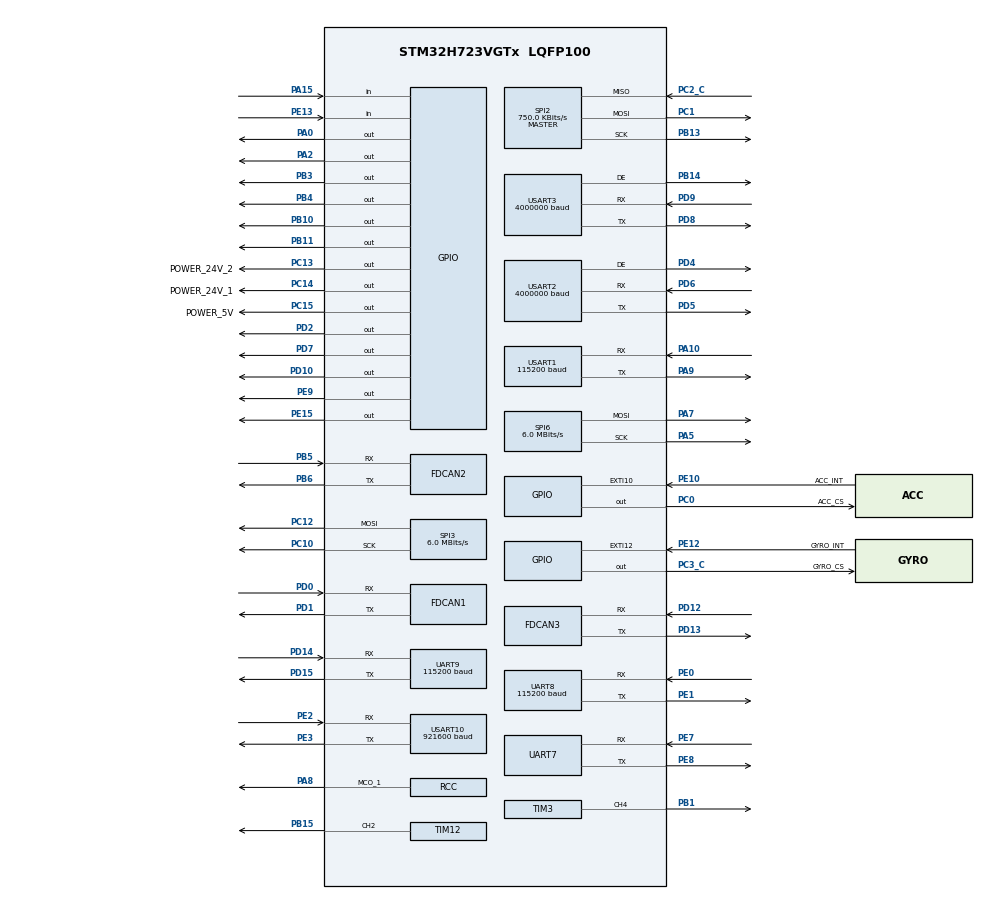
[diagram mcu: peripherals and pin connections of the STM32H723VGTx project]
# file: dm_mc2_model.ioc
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CORTEX_M7.default_mode_Activation=1
Dma.Request0=USART2_RX
Dma.Request1=USART2_TX
Dma.Request10=USART1_RX
Dma.Request11=USART1_TX
Dma.Request12=UART8_RX
Dma.Request13=UART8_TX
Dma.Request14=UART9_TX
Dma.Request15=USART10_TX
Dma.Request2=USART3_RX
Dma.Request3=USART3_TX
Dma.Request4=SPI2_RX
Dma.Request5=SPI2_TX
Dma.Request6=USART10_RX
Dma.Request7=UART7_RX
Dma.Request8=UART7_TX
Dma.Request9=UART9_RX
Dma.SPI2_RX.4.Direction=DMA_PERIPH_TO_MEMORY
Dma.SPI2_RX.4.EventEnable=DISABLE
Dma.SPI2_RX.4.FIFOMode=DMA_FIFOMODE_DISABLE
Dma.SPI2_RX.4.Instance=DMA1_Stream4
Dma.SPI2_RX.4.MemDataAlignment=DMA_MDATAALIGN_BYTE
Dma.SPI2_RX.4.MemInc=DMA_MINC_ENABLE
Dma.SPI2_RX.4.Mode=DMA_NORMAL
Dma.SPI2_RX.4.PeriphDataAlignment=DMA_PDATAALIGN_BYTE
Dma.SPI2_RX.4.PeriphInc=DMA_PINC_DISABLE
Dma.SPI2_RX.4.Polarity=HAL_DMAMUX_REQ_GEN_RISING
Dma.SPI2_RX.4.Priority=DMA_PRIORITY_VERY_HIGH
Dma.SPI2_RX.4.RequestNumber=1
Dma.SPI2_RX.4.SignalID=NONE
Dma.SPI2_RX.4.SyncEnable=DISABLE
Dma.SPI2_RX.4.SyncPolarity=HAL_DMAMUX_SYNC_NO_EVENT
Dma.SPI2_RX.4.SyncRequestNumber=1
Dma.SPI2_RX.4.SyncSignalID=NONE
Dma.SPI2_TX.5.Direction=DMA_MEMORY_TO_PERIPH
Dma.SPI2_TX.5.EventEnable=DISABLE
Dma.SPI2_TX.5.FIFOMode=DMA_FIFOMODE_DISABLE
Dma.SPI2_TX.5.Instance=DMA1_Stream5
Dma.SPI2_TX.5.MemDataAlignment=DMA_MDATAALIGN_BYTE
Dma.SPI2_TX.5.MemInc=DMA_MINC_ENABLE
Dma.SPI2_TX.5.Mode=DMA_NORMAL
Dma.SPI2_TX.5.PeriphDataAlignment=DMA_PDATAALIGN_BYTE
Dma.SPI2_TX.5.PeriphInc=DMA_PINC_DISABLE
Dma.SPI2_TX.5.Polarity=HAL_DMAMUX_REQ_GEN_RISING
Dma.SPI2_TX.5.Priority=DMA_PRIORITY_HIGH
Dma.SPI2_TX.5.RequestNumber=1
Dma.SPI2_TX.5.SignalID=NONE
Dma.SPI2_TX.5.SyncEnable=DISABLE
Dma.SPI2_TX.5.SyncPolarity=HAL_DMAMUX_SYNC_NO_EVENT
Dma.SPI2_TX.5.SyncRequestNumber=1
Dma.SPI2_TX.5.SyncSignalID=NONE
Dma.UART7_RX.7.Direction=DMA_PERIPH_TO_MEMORY
Dma.UART7_RX.7.EventEnable=DISABLE
Dma.UART7_RX.7.FIFOMode=DMA_FIFOMODE_DISABLE
Dma.UART7_RX.7.Instance=DMA1_Stream7
Dma.UART7_RX.7.MemDataAlignment=DMA_MDATAALIGN_BYTE
Dma.UART7_RX.7.MemInc=DMA_MINC_ENABLE
Dma.UART7_RX.7.Mode=DMA_NORMAL
Dma.UART7_RX.7.PeriphDataAlignment=DMA_PDATAALIGN_BYTE
Dma.UART7_RX.7.PeriphInc=DMA_PINC_DISABLE
Dma.UART7_RX.7.Polarity=HAL_DMAMUX_REQ_GEN_RISING
Dma.UART7_RX.7.Priority=DMA_PRIORITY_LOW
Dma.UART7_RX.7.RequestNumber=1
Dma.UART7_RX.7.SignalID=NONE
Dma.UART7_RX.7.SyncEnable=DISABLE
Dma.UART7_RX.7.SyncPolarity=HAL_DMAMUX_SYNC_NO_EVENT
Dma.UART7_RX.7.SyncRequestNumber=1
Dma.UART7_RX.7.SyncSignalID=NONE
Dma.UART7_TX.8.Direction=DMA_MEMORY_TO_PERIPH
Dma.UART7_TX.8.EventEnable=DISABLE
Dma.UART7_TX.8.FIFOMode=DMA_FIFOMODE_DISABLE
Dma.UART7_TX.8.Instance=DMA2_Stream0
Dma.UART7_TX.8.MemDataAlignment=DMA_MDATAALIGN_BYTE
Dma.UART7_TX.8.MemInc=DMA_MINC_ENABLE
Dma.UART7_TX.8.Mode=DMA_NORMAL
Dma.UART7_TX.8.PeriphDataAlignment=DMA_PDATAALIGN_BYTE
Dma.UART7_TX.8.PeriphInc=DMA_PINC_DISABLE
Dma.UART7_TX.8.Polarity=HAL_DMAMUX_REQ_GEN_RISING
Dma.UART7_TX.8.Priority=DMA_PRIORITY_LOW
Dma.UART7_TX.8.RequestNumber=1
Dma.UART7_TX.8.SignalID=NONE
Dma.UART7_TX.8.SyncEnable=DISABLE
Dma.UART7_TX.8.SyncPolarity=HAL_DMAMUX_SYNC_NO_EVENT
Dma.UART7_TX.8.SyncRequestNumber=1
Dma.UART7_TX.8.SyncSignalID=NONE
Dma.UART8_RX.12.Direction=DMA_PERIPH_TO_MEMORY
Dma.UART8_RX.12.EventEnable=DISABLE
Dma.UART8_RX.12.FIFOMode=DMA_FIFOMODE_DISABLE
Dma.UART8_RX.12.Instance=DMA2_Stream4
Dma.UART8_RX.12.MemDataAlignment=DMA_MDATAALIGN_BYTE
Dma.UART8_RX.12.MemInc=DMA_MINC_ENABLE
Dma.UART8_RX.12.Mode=DMA_NORMAL
Dma.UART8_RX.12.PeriphDataAlignment=DMA_PDATAALIGN_BYTE
Dma.UART8_RX.12.PeriphInc=DMA_PINC_DISABLE
Dma.UART8_RX.12.Polarity=HAL_DMAMUX_REQ_GEN_RISING
Dma.UART8_RX.12.Priority=DMA_PRIORITY_LOW
Dma.UART8_RX.12.RequestNumber=1
Dma.UART8_RX.12.SignalID=NONE
Dma.UART8_RX.12.SyncEnable=DISABLE
Dma.UART8_RX.12.SyncPolarity=HAL_DMAMUX_SYNC_NO_EVENT
Dma.UART8_RX.12.SyncRequestNumber=1
Dma.UART8_RX.12.SyncSignalID=NONE
Dma.UART8_TX.13.Direction=DMA_MEMORY_TO_PERIPH
Dma.UART8_TX.13.EventEnable=DISABLE
Dma.UART8_TX.13.FIFOMode=DMA_FIFOMODE_DISABLE
Dma.UART8_TX.13.Instance=DMA2_Stream5
Dma.UART8_TX.13.MemDataAlignment=DMA_MDATAALIGN_BYTE
Dma.UART8_TX.13.MemInc=DMA_MINC_ENABLE
Dma.UART8_TX.13.Mode=DMA_NORMAL
Dma.UART8_TX.13.PeriphDataAlignment=DMA_PDATAALIGN_BYTE
Dma.UART8_TX.13.PeriphInc=DMA_PINC_DISABLE
Dma.UART8_TX.13.Polarity=HAL_DMAMUX_REQ_GEN_RISING
Dma.UART8_TX.13.Priority=DMA_PRIORITY_LOW
Dma.UART8_TX.13.RequestNumber=1
Dma.UART8_TX.13.SignalID=NONE
Dma.UART8_TX.13.SyncEnable=DISABLE
Dma.UART8_TX.13.SyncPolarity=HAL_DMAMUX_SYNC_NO_EVENT
Dma.UART8_TX.13.SyncRequestNumber=1
Dma.UART8_TX.13.SyncSignalID=NONE
Dma.UART9_RX.9.Direction=DMA_PERIPH_TO_MEMORY
Dma.UART9_RX.9.EventEnable=DISABLE
Dma.UART9_RX.9.FIFOMode=DMA_FIFOMODE_DISABLE
Dma.UART9_RX.9.Instance=DMA2_Stream1
Dma.UART9_RX.9.MemDataAlignment=DMA_MDATAALIGN_BYTE
Dma.UART9_RX.9.MemInc=DMA_MINC_ENABLE
Dma.UART9_RX.9.Mode=DMA_NORMAL
Dma.UART9_RX.9.PeriphDataAlignment=DMA_PDATAALIGN_BYTE
Dma.UART9_RX.9.PeriphInc=DMA_PINC_DISABLE
Dma.UART9_RX.9.Polarity=HAL_DMAMUX_REQ_GEN_RISING
Dma.UART9_RX.9.Priority=DMA_PRIORITY_LOW
Dma.UART9_RX.9.RequestNumber=1
Dma.UART9_RX.9.SignalID=NONE
Dma.UART9_RX.9.SyncEnable=DISABLE
Dma.UART9_RX.9.SyncPolarity=HAL_DMAMUX_SYNC_NO_EVENT
Dma.UART9_RX.9.SyncRequestNumber=1
Dma.UART9_RX.9.SyncSignalID=NONE
Dma.UART9_TX.14.Direction=DMA_MEMORY_TO_PERIPH
Dma.UART9_TX.14.EventEnable=DISABLE
Dma.UART9_TX.14.FIFOMode=DMA_FIFOMODE_DISABLE
Dma.UART9_TX.14.Instance=DMA2_Stream6
Dma.UART9_TX.14.MemDataAlignment=DMA_MDATAALIGN_BYTE
Dma.UART9_TX.14.MemInc=DMA_MINC_ENABLE
Dma.UART9_TX.14.Mode=DMA_NORMAL
Dma.UART9_TX.14.PeriphDataAlignment=DMA_PDATAALIGN_BYTE
Dma.UART9_TX.14.PeriphInc=DMA_PINC_DISABLE
Dma.UART9_TX.14.Polarity=HAL_DMAMUX_REQ_GEN_RISING
Dma.UART9_TX.14.Priority=DMA_PRIORITY_LOW
Dma.UART9_TX.14.RequestNumber=1
Dma.UART9_TX.14.SignalID=NONE
Dma.UART9_TX.14.SyncEnable=DISABLE
Dma.UART9_TX.14.SyncPolarity=HAL_DMAMUX_SYNC_NO_EVENT
Dma.UART9_TX.14.SyncRequestNumber=1
Dma.UART9_TX.14.SyncSignalID=NONE
Dma.USART10_RX.6.Direction=DMA_PERIPH_TO_MEMORY
Dma.USART10_RX.6.EventEnable=DISABLE
Dma.USART10_RX.6.FIFOMode=DMA_FIFOMODE_DISABLE
Dma.USART10_RX.6.Instance=DMA1_Stream6
Dma.USART10_RX.6.MemDataAlignment=DMA_MDATAALIGN_BYTE
Dma.USART10_RX.6.MemInc=DMA_MINC_ENABLE
Dma.USART10_RX.6.Mode=DMA_NORMAL
Dma.USART10_RX.6.PeriphDataAlignment=DMA_PDATAALIGN_BYTE
Dma.USART10_RX.6.PeriphInc=DMA_PINC_DISABLE
Dma.USART10_RX.6.Polarity=HAL_DMAMUX_REQ_GEN_RISING
Dma.USART10_RX.6.Priority=DMA_PRIORITY_LOW
Dma.USART10_RX.6.RequestNumber=1
Dma.USART10_RX.6.SignalID=NONE
Dma.USART10_RX.6.SyncEnable=DISABLE
Dma.USART10_RX.6.SyncPolarity=HAL_DMAMUX_SYNC_NO_EVENT
Dma.USART10_RX.6.SyncRequestNumber=1
Dma.USART10_RX.6.SyncSignalID=NONE
Dma.USART10_TX.15.Direction=DMA_MEMORY_TO_PERIPH
Dma.USART10_TX.15.EventEnable=DISABLE
Dma.USART10_TX.15.FIFOMode=DMA_FIFOMODE_DISABLE
Dma.USART10_TX.15.Instance=DMA2_Stream7
Dma.USART10_TX.15.MemDataAlignment=DMA_MDATAALIGN_BYTE
Dma.USART10_TX.15.MemInc=DMA_MINC_ENABLE
Dma.USART10_TX.15.Mode=DMA_NORMAL
Dma.USART10_TX.15.PeriphDataAlignment=DMA_PDATAALIGN_BYTE
Dma.USART10_TX.15.PeriphInc=DMA_PINC_DISABLE
Dma.USART10_TX.15.Polarity=HAL_DMAMUX_REQ_GEN_RISING
Dma.USART10_TX.15.Priority=DMA_PRIORITY_LOW
Dma.USART10_TX.15.RequestNumber=1
Dma.USART10_TX.15.SignalID=NONE
Dma.USART10_TX.15.SyncEnable=DISABLE
Dma.USART10_TX.15.SyncPolarity=HAL_DMAMUX_SYNC_NO_EVENT
Dma.USART10_TX.15.SyncRequestNumber=1
Dma.USART10_TX.15.SyncSignalID=NONE
Dma.USART1_RX.10.Direction=DMA_PERIPH_TO_MEMORY
Dma.USART1_RX.10.EventEnable=DISABLE
Dma.USART1_RX.10.FIFOMode=DMA_FIFOMODE_DISABLE
Dma.USART1_RX.10.Instance=DMA2_Stream2
Dma.USART1_RX.10.MemDataAlignment=DMA_MDATAALIGN_BYTE
Dma.USART1_RX.10.MemInc=DMA_MINC_ENABLE
Dma.USART1_RX.10.Mode=DMA_NORMAL
Dma.USART1_RX.10.PeriphDataAlignment=DMA_PDATAALIGN_BYTE
Dma.USART1_RX.10.PeriphInc=DMA_PINC_DISABLE
Dma.USART1_RX.10.Polarity=HAL_DMAMUX_REQ_GEN_RISING
Dma.USART1_RX.10.Priority=DMA_PRIORITY_LOW
Dma.USART1_RX.10.RequestNumber=1
Dma.USART1_RX.10.SignalID=NONE
Dma.USART1_RX.10.SyncEnable=DISABLE
Dma.USART1_RX.10.SyncPolarity=HAL_DMAMUX_SYNC_NO_EVENT
Dma.USART1_RX.10.SyncRequestNumber=1
Dma.USART1_RX.10.SyncSignalID=NONE
Dma.USART1_TX.11.Direction=DMA_MEMORY_TO_PERIPH
Dma.USART1_TX.11.EventEnable=DISABLE
Dma.USART1_TX.11.FIFOMode=DMA_FIFOMODE_DISABLE
Dma.USART1_TX.11.Instance=DMA2_Stream3
Dma.USART1_TX.11.MemDataAlignment=DMA_MDATAALIGN_BYTE
Dma.USART1_TX.11.MemInc=DMA_MINC_ENABLE
Dma.USART1_TX.11.Mode=DMA_NORMAL
Dma.USART1_TX.11.PeriphDataAlignment=DMA_PDATAALIGN_BYTE
Dma.USART1_TX.11.PeriphInc=DMA_PINC_DISABLE
Dma.USART1_TX.11.Polarity=HAL_DMAMUX_REQ_GEN_RISING
Dma.USART1_TX.11.Priority=DMA_PRIORITY_LOW
Dma.USART1_TX.11.RequestNumber=1
Dma.USART1_TX.11.SignalID=NONE
Dma.USART1_TX.11.SyncEnable=DISABLE
Dma.USART1_TX.11.SyncPolarity=HAL_DMAMUX_SYNC_NO_EVENT
Dma.USART1_TX.11.SyncRequestNumber=1
Dma.USART1_TX.11.SyncSignalID=NONE
Dma.USART2_RX.0.Direction=DMA_PERIPH_TO_MEMORY
Dma.USART2_RX.0.EventEnable=DISABLE
Dma.USART2_RX.0.FIFOMode=DMA_FIFOMODE_DISABLE
Dma.USART2_RX.0.Instance=DMA1_Stream0
Dma.USART2_RX.0.MemDataAlignment=DMA_MDATAALIGN_BYTE
Dma.USART2_RX.0.MemInc=DMA_MINC_ENABLE
Dma.USART2_RX.0.Mode=DMA_NORMAL
Dma.USART2_RX.0.PeriphDataAlignment=DMA_PDATAALIGN_BYTE
Dma.USART2_RX.0.PeriphInc=DMA_PINC_DISABLE
Dma.USART2_RX.0.Polarity=HAL_DMAMUX_REQ_GEN_RISING
Dma.USART2_RX.0.Priority=DMA_PRIORITY_LOW
Dma.USART2_RX.0.RequestNumber=1
Dma.USART2_RX.0.SignalID=NONE
Dma.USART2_RX.0.SyncEnable=DISABLE
Dma.USART2_RX.0.SyncPolarity=HAL_DMAMUX_SYNC_NO_EVENT
Dma.USART2_RX.0.SyncRequestNumber=1
Dma.USART2_RX.0.SyncSignalID=NONE
Dma.USART2_TX.1.Direction=DMA_MEMORY_TO_PERIPH
Dma.USART2_TX.1.EventEnable=DISABLE
Dma.USART2_TX.1.FIFOMode=DMA_FIFOMODE_DISABLE
Dma.USART2_TX.1.Instance=DMA1_Stream1
Dma.USART2_TX.1.MemDataAlignment=DMA_MDATAALIGN_BYTE
Dma.USART2_TX.1.MemInc=DMA_MINC_ENABLE
Dma.USART2_TX.1.Mode=DMA_NORMAL
Dma.USART2_TX.1.PeriphDataAlignment=DMA_PDATAALIGN_BYTE
Dma.USART2_TX.1.PeriphInc=DMA_PINC_DISABLE
Dma.USART2_TX.1.Polarity=HAL_DMAMUX_REQ_GEN_RISING
Dma.USART2_TX.1.Priority=DMA_PRIORITY_LOW
Dma.USART2_TX.1.RequestNumber=1
Dma.USART2_TX.1.SignalID=NONE
Dma.USART2_TX.1.SyncEnable=DISABLE
Dma.USART2_TX.1.SyncPolarity=HAL_DMAMUX_SYNC_NO_EVENT
Dma.USART2_TX.1.SyncRequestNumber=1
Dma.USART2_TX.1.SyncSignalID=NONE
Dma.USART3_RX.2.Direction=DMA_PERIPH_TO_MEMORY
Dma.USART3_RX.2.EventEnable=DISABLE
Dma.USART3_RX.2.FIFOMode=DMA_FIFOMODE_DISABLE
Dma.USART3_RX.2.Instance=DMA1_Stream2
Dma.USART3_RX.2.MemDataAlignment=DMA_MDATAALIGN_BYTE
Dma.USART3_RX.2.MemInc=DMA_MINC_ENABLE
Dma.USART3_RX.2.Mode=DMA_NORMAL
Dma.USART3_RX.2.PeriphDataAlignment=DMA_PDATAALIGN_BYTE
Dma.USART3_RX.2.PeriphInc=DMA_PINC_DISABLE
Dma.USART3_RX.2.Polarity=HAL_DMAMUX_REQ_GEN_RISING
Dma.USART3_RX.2.Priority=DMA_PRIORITY_LOW
Dma.USART3_RX.2.RequestNumber=1
Dma.USART3_RX.2.SignalID=NONE
Dma.USART3_RX.2.SyncEnable=DISABLE
Dma.USART3_RX.2.SyncPolarity=HAL_DMAMUX_SYNC_NO_EVENT
Dma.USART3_RX.2.SyncRequestNumber=1
Dma.USART3_RX.2.SyncSignalID=NONE
Dma.USART3_TX.3.Direction=DMA_MEMORY_TO_PERIPH
Dma.USART3_TX.3.EventEnable=DISABLE
Dma.USART3_TX.3.FIFOMode=DMA_FIFOMODE_DISABLE
Dma.USART3_TX.3.Instance=DMA1_Stream3
Dma.USART3_TX.3.MemDataAlignment=DMA_MDATAALIGN_BYTE
Dma.USART3_TX.3.MemInc=DMA_MINC_ENABLE
Dma.USART3_TX.3.Mode=DMA_NORMAL
Dma.USART3_TX.3.PeriphDataAlignment=DMA_PDATAALIGN_BYTE
Dma.USART3_TX.3.PeriphInc=DMA_PINC_DISABLE
Dma.USART3_TX.3.Polarity=HAL_DMAMUX_REQ_GEN_RISING
Dma.USART3_TX.3.Priority=DMA_PRIORITY_LOW
Dma.USART3_TX.3.RequestNumber=1
Dma.USART3_TX.3.SignalID=NONE
Dma.USART3_TX.3.SyncEnable=DISABLE
Dma.USART3_TX.3.SyncPolarity=HAL_DMAMUX_SYNC_NO_EVENT
Dma.USART3_TX.3.SyncRequestNumber=1
Dma.USART3_TX.3.SyncSignalID=NONE
FDCAN1.CalculateBaudRateNominal=1000000
FDCAN1.CalculateTimeBitNominal=1000
FDCAN1.CalculateTimeQuantumNominal=200.0
FDCAN1.NominalPrescaler=24
FDCAN1.NominalTimeSeg1=2
FDCAN1.NominalTimeSeg2=2
FDCAN1.RxFifo0ElmtsNbr=32
FDCAN1.StdFiltersNbr=1
FDCAN1.TxFifoQueueElmtsNbr=32
FDCAN2.CalculateBaudRateNominal=1000000
FDCAN2.CalculateTimeBitNominal=1000
FDCAN2.CalculateTimeQuantumNominal=100.0
FDCAN2.MessageRAMOffset=0x406
FDCAN2.NominalPrescaler=12
FDCAN2.NominalSyncJumpWidth=2
FDCAN2.NominalTimeSeg1=7
FDCAN2.NominalTimeSeg2=2
FDCAN2.RxFifo0ElmtsNbr=32
FDCAN2.StdFiltersNbr=1
FDCAN2.TxFifoQueueElmtsNbr=32
FDCAN3.CalculateBaudRateNominal=1000000
FDCAN3.CalculateTimeBitNominal=1000
FDCAN3.CalculateTimeQuantumNominal=200.0
FDCAN3.MessageRAMOffset=0x812
FDCAN3.NominalPrescaler=24
FDCAN3.NominalTimeSeg1=2
FDCAN3.NominalTimeSeg2=2
FDCAN3.RxFifo0ElmtsNbr=32
FDCAN3.StdFiltersNbr=1
FDCAN3.TxFifoQueueElmtsNbr=32
FREERTOS.Tasks01=defaultTask,24,128,StartDefaultTask,Default,NULL,Dynamic,NULL,NULL;Unitree,8,128,Unitree_Function,Default,NULL,Dynamic,NULL,NULL;DM,8,128,DM_Function,Default,NULL,Dynamic,NULL,NULL;DJI,8,128,DJI_Function,Default,NULL,Dynamic,NULL,NULL;Remote,8,128,Remote_Function,Default,NULL,Dynamic,NULL,NULL;DH_C,8,128,DH_C_Function,Default,NULL,Dynamic,NULL,NULL;Remote_mode,8,128,Remote_mode_function,Default,NULL,Dynamic,NULL,NULL;inverseKinemati,8,128,inverseKinematics_Function,Default,NULL,Dynamic,NULL,NULL;Angle_ring,8,128,Angle_ring_Function,Default,NULL,Dynamic,NULL,NULL;L1_Mode,8,128,L1_Mode_Function,Default,NULL,Dynamic,NULL,NULL;Lift_Mode,8,128,Lift_Mode_Function,Default,NULL,Dynamic,NULL,NULL;One_Area,8,128,One_Area_Function,Default,NULL,Dynamic,NULL,NULL;Two_Area,8,128,Two_Area_Function,Default,NULL,Dynamic,NULL,NULL;Three_Area,8,128,Three_Area_Function,Default,NULL,Dynamic,NULL,NULL;Mid360,8,128,Mid360_Function,Default,NULL,Dynamic,NULL,NULL;Track_Mode,8,128,Track_Mode_Function,Default,NULL,Dynamic,NULL,NULL
Mcu.Family=STM32H7
Mcu.Name=STM32H723VGTx
Mcu.Package=LQFP100
NVIC.DMA1_Stream0_IRQn=true\:5\:0\:false\:false\:true\:true\:false\:true\:true
NVIC.DMA1_Stream1_IRQn=true\:5\:0\:false\:false\:true\:true\:false\:true\:true
NVIC.DMA1_Stream2_IRQn=true\:5\:0\:false\:false\:true\:true\:false\:true\:true
NVIC.DMA1_Stream3_IRQn=true\:5\:0\:false\:false\:true\:true\:false\:true\:true
NVIC.DMA1_Stream4_IRQn=true\:5\:0\:false\:false\:true\:true\:false\:true\:true
NVIC.DMA1_Stream5_IRQn=true\:5\:0\:false\:false\:true\:true\:false\:true\:true
NVIC.DMA1_Stream6_IRQn=true\:5\:0\:false\:false\:true\:true\:false\:true\:true
NVIC.DMA1_Stream7_IRQn=true\:5\:0\:false\:false\:true\:true\:false\:true\:true
NVIC.DMA2_Stream0_IRQn=true\:5\:0\:false\:false\:true\:true\:false\:true\:true
NVIC.DMA2_Stream1_IRQn=true\:5\:0\:false\:false\:true\:true\:false\:true\:true
NVIC.DMA2_Stream2_IRQn=true\:5\:0\:false\:false\:true\:true\:false\:true\:true
NVIC.DMA2_Stream3_IRQn=true\:5\:0\:false\:false\:true\:true\:false\:true\:true
NVIC.DMA2_Stream4_IRQn=true\:5\:0\:false\:false\:true\:true\:false\:true\:true
NVIC.DMA2_Stream5_IRQn=true\:5\:0\:false\:false\:true\:true\:false\:true\:true
NVIC.DMA2_Stream6_IRQn=true\:5\:0\:false\:false\:true\:true\:false\:true\:true
NVIC.DMA2_Stream7_IRQn=true\:5\:0\:false\:false\:true\:true\:false\:true\:true
NVIC.FDCAN1_IT0_IRQn=true\:5\:0\:false\:false\:true\:true\:true\:true\:true
NVIC.FDCAN1_IT1_IRQn=true\:5\:0\:false\:false\:true\:true\:true\:true\:true
NVIC.FDCAN2_IT0_IRQn=true\:5\:0\:false\:false\:true\:true\:true\:true\:true
NVIC.FDCAN2_IT1_IRQn=true\:5\:0\:false\:false\:true\:true\:true\:true\:true
NVIC.FDCAN3_IT0_IRQn=true\:5\:0\:false\:false\:true\:true\:true\:true\:true
NVIC.FDCAN3_IT1_IRQn=true\:5\:0\:false\:false\:true\:true\:true\:true\:true
NVIC.PriorityGroup=NVIC_PRIORITYGROUP_4
NVIC.SPI2_IRQn=true\:5\:0\:false\:false\:true\:true\:false\:true\:true
NVIC.TIM23_IRQn=true\:15\:0\:false\:false\:true\:false\:false\:true\:true
NVIC.TIM6_DAC_IRQn=true\:5\:0\:false\:false\:true\:true\:true\:true\:true
NVIC.TimeBase=TIM23_IRQn
NVIC.TimeBaseIP=TIM23
NVIC.UART7_IRQn=true\:5\:0\:false\:false\:true\:true\:true\:true\:true
NVIC.UART8_IRQn=true\:5\:0\:false\:false\:true\:true\:true\:true\:true
NVIC.UART9_IRQn=true\:5\:0\:false\:false\:true\:true\:true\:true\:true
NVIC.USART10_IRQn=true\:5\:0\:false\:false\:true\:true\:true\:true\:true
NVIC.USART1_IRQn=true\:5\:0\:false\:false\:true\:true\:true\:true\:true
NVIC.USART2_IRQn=true\:5\:0\:false\:false\:true\:true\:true\:true\:true
NVIC.USART3_IRQn=true\:5\:0\:false\:false\:true\:true\:true\:true\:true
PA0.Signal=GPIO_Output
PA1.Signal=OCTOSPIM_P1_IO3
PA10.Mode=Asynchronous
PA10.Signal=USART1_RX
PA13(JTMS/SWDIO).Mode=Serial_Wire
PA13(JTMS/SWDIO).Signal=DEBUG_JTMS-SWDIO
PA14(JTCK/SWCLK).Mode=Serial_Wire
PA14(JTCK/SWCLK).Signal=DEBUG_JTCK-SWCLK
PA15(JTDI).Signal=GPIO_Input
PA2.Signal=GPIO_Output
PA3.Signal=OCTOSPIM_P1_IO2
PA5.Mode=TX_Only_Simplex_Unidirect_Master
PA5.Signal=SPI6_SCK
PA7.GPIO_Speed=GPIO_SPEED_FREQ_VERY_HIGH
PA7.Mode=TX_Only_Simplex_Unidirect_Master
PA7.Signal=SPI6_MOSI
PA8.Mode=Clock-out-1
PA8.Signal=RCC_MCO_1
PA9.Mode=Asynchronous
PA9.Signal=USART1_TX
PB1.Signal=S_TIM3_CH4
PB10.Signal=GPIO_Output
PB11.Signal=GPIO_Output
PB13.Mode=Full_Duplex_Master
PB13.Signal=SPI2_SCK
PB14.Mode=Hardware Flow Control (RS485)
PB14.Signal=USART3_DE
PB15.Signal=S_TIM12_CH2
PB3(JTDO/TRACESWO).Signal=GPIO_Output
PB4(NJTRST).Signal=GPIO_Output
PB5.Mode=FDCAN_Activate
PB5.Signal=FDCAN2_RX
PB6.Mode=FDCAN_Activate
PB6.Signal=FDCAN2_TX
PC0.GPIO_Label=ACC_CS
PC0.GPIO_Speed=GPIO_SPEED_FREQ_VERY_HIGH
PC0.PinState=GPIO_PIN_SET
PC0.Signal=GPIO_Output
PC1.Mode=Full_Duplex_Master
PC1.Signal=SPI2_MOSI
PC10.Mode=TX_Only_Simplex_Unidirect_Master
PC10.Signal=SPI3_SCK
PC11.Signal=SPI3_MISO
PC12.Mode=TX_Only_Simplex_Unidirect_Master
PC12.Signal=SPI3_MOSI
PC13.GPIO_Label=POWER_24V_2
PC13.PinState=GPIO_PIN_SET
PC13.Signal=GPIO_Output
PC14-OSC32_IN.GPIO_Label=POWER_24V_1
PC14-OSC32_IN.PinState=GPIO_PIN_SET
PC14-OSC32_IN.Signal=GPIO_Output
PC15-OSC32_OUT.GPIO_Label=POWER_5V
PC15-OSC32_OUT.PinState=GPIO_PIN_SET
PC15-OSC32_OUT.Signal=GPIO_Output
PC2_C.Mode=Full_Duplex_Master
PC2_C.Signal=SPI2_MISO
PC3_C.GPIO_Label=GYRO_CS
PC3_C.GPIO_Speed=GPIO_SPEED_FREQ_VERY_HIGH
PC3_C.PinState=GPIO_PIN_SET
PC3_C.Signal=GPIO_Output
PD0.Mode=FDCAN_Activate
PD0.Signal=FDCAN1_RX
PD1.Mode=FDCAN_Activate
PD1.Signal=FDCAN1_TX
PD10.Signal=GPIO_Output
PD12.Mode=FDCAN_Activate
PD12.Signal=FDCAN3_RX
PD13.Mode=FDCAN_Activate
PD13.Signal=FDCAN3_TX
PD14.Mode=Asynchronous
PD14.Signal=UART9_RX
PD15.Mode=Asynchronous
PD15.Signal=UART9_TX
PD2.Signal=GPIO_Output
PD4.Mode=Hardware Flow Control (RS485)
PD4.Signal=USART2_DE
PD5.Mode=Asynchronous
PD5.Signal=USART2_TX
PD6.Mode=Asynchronous
PD6.Signal=USART2_RX
PD7.Signal=GPIO_Output
PD8.Mode=Asynchronous
PD8.Signal=USART3_TX
PD9.Mode=Asynchronous
PD9.Signal=USART3_RX
PE0.Mode=Asynchronous
PE0.Signal=UART8_RX
PE1.Mode=Asynchronous
PE1.Signal=UART8_TX
PE10.GPIO_Label=ACC_INT
PE10.Signal=GPXTI10
PE12.GPIO_Label=GYRO_INT
PE12.Signal=GPXTI12
PE13.GPIO_PuPd=GPIO_NOPULL
PE13.Signal=GPIO_Input
PE15.Signal=GPIO_Output
PE2.Mode=Asynchronous
PE2.Signal=USART10_RX
PE3.Mode=Asynchronous
PE3.Signal=USART10_TX
PE7.Mode=Asynchronous
PE7.Signal=UART7_RX
PE8.Mode=Asynchronous
PE8.Signal=UART7_TX
PE9.Signal=GPIO_Output
PH0-OSC_IN.Mode=HSE-External-Oscillator
PH0-OSC_IN.Signal=RCC_OSC_IN
PH1-OSC_OUT.Mode=HSE-External-Oscillator
PH1-OSC_OUT.Signal=RCC_OSC_OUT
ProjectManager.HeapSize=0x200
ProjectManager.StackSize=0x400
ProjectManager.TargetToolchain=STM32CubeIDE
RCC.ADCFreq_Value=96000000
RCC.APB1Freq_Value=120000000
RCC.APB2Freq_Value=120000000
RCC.APB3Freq_Value=120000000
RCC.APB4Freq_Value=120000000
RCC.CKPERSourceSelection=RCC_CLKPSOURCE_HSE
RCC.CortexFreq_Value=480000000
RCC.D1PPRE=RCC_APB3_DIV2
RCC.D2PPRE1=RCC_APB1_DIV2
RCC.D2PPRE2=RCC_APB2_DIV2
RCC.D3PPRE=RCC_APB4_DIV2
RCC.DIVM1=2
RCC.DIVM2=2
RCC.DIVN1=40
RCC.DIVN2=16
RCC.DIVP1=1
RCC.DIVQ1=4
RCC.HCLKFreq_Value=240000000
RCC.HPRE=RCC_HCLK_DIV2
RCC.HSE_VALUE=24000000
RCC.PLL2FRACN=0
RCC.PLL3FRACN=0
RCC.PLL3_VCI_Range-AdvancedSettings=RCC_PLL3VCIRANGE_3
RCC.PLLFRACN=0
RCC.PLLSourceVirtual=RCC_PLLSOURCE_HSE
RCC.SPI123CLockSelection=RCC_SPI123CLKSOURCE_CLKP
RCC.SPI6CLockSelection=RCC_SPI6CLKSOURCE_HSE
RCC.SYSCLKFreq_VALUE=480000000
RCC.SYSCLKSource=RCC_SYSCLKSOURCE_PLLCLK
RCC.USBFreq_Value=120000000
SH.S_TIM12_CH2.0=TIM12_CH2,PWM Generation2 CH2
SH.S_TIM3_CH4.0=TIM3_CH4,PWM Generation4 CH4
SPI2.BaudRatePrescaler=SPI_BAUDRATEPRESCALER_32
SPI2.CLKPhase=SPI_PHASE_2EDGE
SPI2.CLKPolarity=SPI_POLARITY_HIGH
SPI2.CalculateBaudRate=750.0 KBits/s
SPI2.DataSize=SPI_DATASIZE_8BIT
SPI2.Direction=SPI_DIRECTION_2LINES
SPI2.Mode=SPI_MODE_MASTER
SPI2.VirtualType=VM_MASTER
SPI3.BaudRatePrescaler=SPI_BAUDRATEPRESCALER_4
SPI3.CLKPhase=SPI_PHASE_2EDGE
SPI3.CalculateBaudRate=6.0 MBits/s
SPI3.DataSize=SPI_DATASIZE_8BIT
SPI3.Direction=SPI_DIRECTION_2LINES_TXONLY
SPI3.Mode=SPI_MODE_MASTER
SPI3.VirtualType=VM_MASTER
SPI6.BaudRatePrescaler=SPI_BAUDRATEPRESCALER_4
SPI6.CLKPhase=SPI_PHASE_2EDGE
SPI6.CalculateBaudRate=6.0 MBits/s
SPI6.DataSize=SPI_DATASIZE_8BIT
SPI6.Direction=SPI_DIRECTION_2LINES_TXONLY
SPI6.Mode=SPI_MODE_MASTER
SPI6.VirtualType=VM_MASTER
STMicroelectronics.X-CUBE-ALGOBUILD.1.4.0.LibraryCcDSPOoLibraryJjDSPOoLibrary=true
TIM12.Channel-PWM\ Generation2\ CH2=TIM_CHANNEL_2
TIM12.Period=2000-1
TIM12.Prescaler=24-1
TIM3.AutoReloadPreload=TIM_AUTORELOAD_PRELOAD_ENABLE
TIM3.Channel-PWM\ Generation4\ CH4=TIM_CHANNEL_4
TIM3.Period=10000-1
TIM3.Prescaler=24-1
TIM6.AutoReloadPreload=TIM_AUTORELOAD_PRELOAD_ENABLE
TIM6.Period=999
TIM6.Prescaler=4799
UART8.BaudRate=115200
UART8.FIFOMode=FIFOMODE_ENABLE
UART9.BaudRate=115200
UART9.FIFOMode=FIFOMODE_ENABLE
USART1.BaudRate=115200
USART1.FIFOMode=FIFOMODE_DISABLE
USART1.VirtualMode-Asynchronous=VM_ASYNC
USART10.BaudRate=921600
USART10.FIFOMode=FIFOMODE_ENABLE
USART10.VirtualMode=VM_ASYNC
USART2.BaudRate=4000000
USART2.UART_DEAssertionTime=0
USART2.UART_DEDeassertionTime=0
USART2.VirtualMode-Asynchronous=VM_ASYNC
USART2.VirtualMode-Hardware\ Flow\ Control\ (RS485)=VM_ASYNC
USART3.BaudRate=4000000
USART3.VirtualMode-Asynchronous=VM_ASYNC
USART3.VirtualMode-Hardware\ Flow\ Control\ (RS485)=VM_ASYNC
VP_FREERTOS_VS_CMSIS_V2.Mode=CMSIS_V2
VP_MEMORYMAP_VS_MEMORYMAP.Mode=CurAppReg
VP_STMicroelectronics.X-CUBE-ALGOBUILD_VS_DSPOoLibraryJjLibrary_1.4.0_1.4.0.Mode=DSPOoLibraryJjLibrary
VP_SYS_VS_tim23.Mode=TIM23
VP_TIM6_VS_ClockSourceINT.Mode=Enable_Timer
board=custom

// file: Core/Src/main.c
/* USER CODE BEGIN Header */
//written by Fred Xiao
/**
  ******************************************************************************
  * @file           : main.c
  * @brief          : Main program body
  ******************************************************************************
  * @attention
  *
  * Copyright (c) 2026 STMicroelectronics.
  * All rights reserved.
  *
  * This software is licensed under terms that can be found in the LICENSE file
  * in the root directory of this software component.
  * If no LICENSE file comes with this software, it is provided AS-IS.
  *
  ******************************************************************************
  */
/* USER CODE END Header */
#include "main.h"
#include "cmsis_os.h"
#include "dma.h"
#include "fdcan.h"
#include "spi.h"
#include "tim.h"
#include "usart.h"
#include "gpio.h"

/* USER CODE BEGIN Includes */
#include "arm_planning.h"

/* USER CODE END Includes */

/* USER CODE BEGIN PV */
uint8_t r = 1;
uint8_t g = 1;
uint8_t b = 255;

/* USER CODE END PV */

void SystemClock_Config(void);
void PeriphCommonClock_Config(void);
static void MPU_Config(void);
void MX_FREERTOS_Init(void);

int main(void)
{

  /* MPU Configuration--------------------------------------------------------*/
  MPU_Config();

  /* MCU Configuration--------------------------------------------------------*/

  /* Reset of all peripherals, Initializes the Flash interface and the Systick. */
  HAL_Init();

  /* Configure the system clock */
  SystemClock_Config();

  /* Configure the peripherals common clocks */
  PeriphCommonClock_Config();

  /* Initialize all configured peripherals */
  MX_GPIO_Init();
  MX_DMA_Init();
  MX_FDCAN1_Init();
  MX_FDCAN2_Init();
  MX_FDCAN3_Init();
  MX_TIM3_Init();
  MX_TIM12_Init();
  MX_USART1_UART_Init();
  MX_USART2_UART_Init();
  MX_USART3_UART_Init();
  MX_SPI2_Init();
  MX_TIM6_Init();
  MX_USART10_UART_Init();
  MX_UART7_Init();
  MX_UART9_Init();
  MX_SPI3_Init();
  MX_UART8_Init();
  MX_SPI6_Init();
  /* USER CODE BEGIN 2 */

  L1_Init(&L1_Sensor1, &huart9);
  L1_Init(&L1_Sensor2, &huart8);

  fdcan_filter_init();
  PID_Init_All();

  float measure_noise = 0.1f;    // 测量噪声(相信传感器)
  float process_noise = 0.01f;   // 过程噪声(相信模型)
  Kalman_Init(&filter, 0.0f, 1.0f, process_noise, measure_noise);

  WS2812_Ctrl(r, g, b);

  Chassis_Force_Control_Init(&chassis_controller);

  unitree_init();

  while(unitree_angle_init[3] == 0)
  {
    unitree_cmd_create(&unitree_cmd[3], 3, 1, 0.0, 0.0, 0, 0.0, 0.0);
    unitree_communicate(3);
    HAL_Delay(100);
  }

  arm_unitree_planning_init();

  DM_Motor_Init();

  HAL_TIM_Base_Start_IT(&htim6);

  //RGB变白，顺利启动
  RGB_Color_Ctrl(255,1,255);

  R2_Extern.work_mode = 1;
  R2_Extern.lift_mood = 1;
  fangkuang_open_1();
  fangkuang_open_2();
  // fangkuang_close_1();
  // fangkuang_close_2();
  R2_Extern.angle_balance_target = 0;
  // qibeng_open();
  R2_Extern.Track_Mode = 1;//0红，1蓝
  R2_Extern.Track_flag = 1;
  R2_Extern.angle3 = 0;
  // visual_data.hmi_start = 1;

  // zhuazi_open();
  // R2_Extern.angle_balance_target = -90;
  // chsaaic_behind_up();
  // chsaaic_front_up();

  HAL_Delay(1000);

  /* USER CODE END 2 */

  /* Init scheduler */
  osKernelInitialize();  /* Call init function for freertos objects (in cmsis_os2.c) */
  MX_FREERTOS_Init();

  /* Start scheduler */
  osKernelStart();

  /* We should never get here as control is now taken by the scheduler */

  /* Infinite loop */
  while (1)
  {

  }
}

void SystemClock_Config(void)
{
  RCC_OscInitTypeDef RCC_OscInitStruct = {0};
  RCC_ClkInitTypeDef RCC_ClkInitStruct = {0};

  /** Supply configuration update enable
  */
  HAL_PWREx_ConfigSupply(PWR_LDO_SUPPLY);

  /** Configure the main internal regulator output voltage
  */
  __HAL_PWR_VOLTAGESCALING_CONFIG(PWR_REGULATOR_VOLTAGE_SCALE0);

  while(!__HAL_PWR_GET_FLAG(PWR_FLAG_VOSRDY)) {}

  /** Initializes the RCC Oscillators according to the specified parameters
  * in the RCC_OscInitTypeDef structure.
  */
  RCC_OscInitStruct.OscillatorType = RCC_OSCILLATORTYPE_HSI|RCC_OSCILLATORTYPE_HSE;
  RCC_OscInitStruct.HSEState = RCC_HSE_ON;
  RCC_OscInitStruct.HSIState = RCC_HSI_DIV1;
  RCC_OscInitStruct.HSICalibrationValue = 64;
  RCC_OscInitStruct.PLL.PLLState = RCC_PLL_ON;
  RCC_OscInitStruct.PLL.PLLSource = RCC_PLLSOURCE_HSE;
  RCC_OscInitStruct.PLL.PLLM = 2;
  RCC_OscInitStruct.PLL.PLLN = 40;
  RCC_OscInitStruct.PLL.PLLP = 1;
  RCC_OscInitStruct.PLL.PLLQ = 4;
  RCC_OscInitStruct.PLL.PLLR = 2;
  RCC_OscInitStruct.PLL.PLLRGE = RCC_PLL1VCIRANGE_3;
  RCC_OscInitStruct.PLL.PLLVCOSEL = RCC_PLL1VCOWIDE;
  RCC_OscInitStruct.PLL.PLLFRACN = 0;
  if (HAL_RCC_OscConfig(&RCC_OscInitStruct) != HAL_OK)
  {
    Error_Handler();
  }

  /** Initializes the CPU, AHB and APB buses clocks
  */
  RCC_ClkInitStruct.ClockType = RCC_CLOCKTYPE_HCLK|RCC_CLOCKTYPE_SYSCLK
                              |RCC_CLOCKTYPE_PCLK1|RCC_CLOCKTYPE_PCLK2
                              |RCC_CLOCKTYPE_D3PCLK1|RCC_CLOCKTYPE_D1PCLK1;
  RCC_ClkInitStruct.SYSCLKSource = RCC_SYSCLKSOURCE_PLLCLK;
  RCC_ClkInitStruct.SYSCLKDivider = RCC_SYSCLK_DIV1;
  RCC_ClkInitStruct.AHBCLKDivider = RCC_HCLK_DIV2;
  RCC_ClkInitStruct.APB3CLKDivider = RCC_APB3_DIV2;
  RCC_ClkInitStruct.APB1CLKDivider = RCC_APB1_DIV2;
  RCC_ClkInitStruct.APB2CLKDivider = RCC_APB2_DIV2;
  RCC_ClkInitStruct.APB4CLKDivider = RCC_APB4_DIV2;

  if (HAL_RCC_ClockConfig(&RCC_ClkInitStruct, FLASH_LATENCY_3) != HAL_OK)
  {
    Error_Handler();
  }
  HAL_RCC_MCOConfig(RCC_MCO1, RCC_MCO1SOURCE_HSI, RCC_MCODIV_1);
}

void PeriphCommonClock_Config(void)
{
  RCC_PeriphCLKInitTypeDef PeriphClkInitStruct = {0};

  /** Initializes the peripherals clock
  */
  PeriphClkInitStruct.PeriphClockSelection = RCC_PERIPHCLK_CKPER;
  PeriphClkInitStruct.CkperClockSelection = RCC_CLKPSOURCE_HSE;
  if (HAL_RCCEx_PeriphCLKConfig(&PeriphClkInitStruct) != HAL_OK)
  {
    Error_Handler();
  }
}

 /* MPU Configuration */

void MPU_Config(void)
{
  MPU_Region_InitTypeDef MPU_InitStruct = {0};

  /* Disables the MPU */
  HAL_MPU_Disable();

  /** Initializes and configures the Region and the memory to be protected
  */
  MPU_InitStruct.Enable = MPU_REGION_ENABLE;
  MPU_InitStruct.Number = MPU_REGION_NUMBER0;
  MPU_InitStruct.BaseAddress = 0x0;
  MPU_InitStruct.Size = MPU_REGION_SIZE_4GB;
  MPU_InitStruct.SubRegionDisable = 0x87;
  MPU_InitStruct.TypeExtField = MPU_TEX_LEVEL0;
  MPU_InitStruct.AccessPermission = MPU_REGION_NO_ACCESS;
  MPU_InitStruct.DisableExec = MPU_INSTRUCTION_ACCESS_DISABLE;
  MPU_InitStruct.IsShareable = MPU_ACCESS_SHAREABLE;
  MPU_InitStruct.IsCacheable = MPU_ACCESS_NOT_CACHEABLE;
  MPU_InitStruct.IsBufferable = MPU_ACCESS_NOT_BUFFERABLE;

  HAL_MPU_ConfigRegion(&MPU_InitStruct);
  /* Enables the MPU */
  HAL_MPU_Enable(MPU_PRIVILEGED_DEFAULT);

}

void HAL_TIM_PeriodElapsedCallback(TIM_HandleTypeDef *htim)
{
  if (htim->Instance == TIM23)
  {
    HAL_IncTick();
  }
  /* USER CODE BEGIN Callback 1 */
  if (htim->Instance == TIM6)
  {
    PID_Calc_All();
    chassic_small();

    RC_Data_To_Chassis_Target();
    Chassis_Force_Control_Update(&chassis_controller);

  }

  /* USER CODE END Callback 1 */
}

void Error_Handler(void)
{
  __disable_irq();
  while (1)
  {
  }
}

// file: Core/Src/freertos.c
/* USER CODE BEGIN Header */
/**
  ******************************************************************************
  * File Name          : freertos.c
  * Description        : Code for freertos applications
  ******************************************************************************
  * @attention
  *
  * Copyright (c) 2026 STMicroelectronics.
  * All rights reserved.
  *
  * This software is licensed under terms that can be found in the LICENSE file
  * in the root directory of this software component.
  * If no LICENSE file comes with this software, it is provided AS-IS.
  *
  ******************************************************************************
  */
/* USER CODE END Header */

#include "FreeRTOS.h"
#include "task.h"
#include "main.h"
#include "cmsis_os.h"

/* USER CODE BEGIN Variables */
static uint8_t kfs_count_total_ready = 0U;

#define ANGLE_RING_MAX_SPEED_DPS       120.0f
#define ANGLE_RING_MIN_DURATION_S      0.25f
#define ANGLE_RING_TARGET_EPSILON_DEG  0.1f

static float angle_ring_absf(float value)
{
  return (value >= 0.0f) ? value : -value;
}

static float angle_ring_normalize_deg(float angle)
{
  while(angle > 180.0f)
  {
    angle -= 360.0f;
  }
  while(angle < -180.0f)
  {
    angle += 360.0f;
  }
  return angle;
}

static int calc_kfs_count_total(void)
{
  int total = 0;
  uint8_t count = visual_data.meilin_count;

  if(count > 10U)
  {
    count = 10U;
  }

  for(uint8_t i = 0U; i < count; i++)
  {
    MeilinPointCmd point = visual_data.meilin_points[i];

    if(point.has_true_kfs == 1U || point.cell == 13U || point.cell == 15U)
    {
      total++;
    }
  }

  return total;
}
/* USER CODE END Variables */
/* Definitions for defaultTask */
osThreadId_t defaultTaskHandle;
const osThreadAttr_t defaultTask_attributes = {
  .name = "defaultTask",
  .stack_size = 128 * 4,
  .priority = (osPriority_t) osPriorityNormal,
};
/* Definitions for Unitree */
osThreadId_t UnitreeHandle;
const osThreadAttr_t Unitree_attributes = {
  .name = "Unitree",
  .stack_size = 128 * 4,
  .priority = (osPriority_t) osPriorityLow,
};
/* Definitions for DM */
osThreadId_t DMHandle;
const osThreadAttr_t DM_attributes = {
  .name = "DM",
  .stack_size = 128 * 4,
  .priority = (osPriority_t) osPriorityLow,
};
/* Definitions for DJI */
osThreadId_t DJIHandle;
const osThreadAttr_t DJI_attributes = {
  .name = "DJI",
  .stack_size = 128 * 4,
  .priority = (osPriority_t) osPriorityLow,
};
/* Definitions for Remote */
osThreadId_t RemoteHandle;
const osThreadAttr_t Remote_attributes = {
  .name = "Remote",
  .stack_size = 128 * 4,
  .priority = (osPriority_t) osPriorityLow,
};
/* Definitions for DH_C */
osThreadId_t DH_CHandle;
const osThreadAttr_t DH_C_attributes = {
  .name = "DH_C",
  .stack_size = 128 * 4,
  .priority = (osPriority_t) osPriorityLow,
};
/* Definitions for Remote_mode */
osThreadId_t Remote_modeHandle;
const osThreadAttr_t Remote_mode_attributes = {
  .name = "Remote_mode",
  .stack_size = 128 * 4,
  .priority = (osPriority_t) osPriorityLow,
};
/* Definitions for inverseKinemati */
osThreadId_t inverseKinematiHandle;
const osThreadAttr_t inverseKinemati_attributes = {
  .name = "inverseKinemati",
  .stack_size = 128 * 4,
  .priority = (osPriority_t) osPriorityLow,
};
/* Definitions for Angle_ring */
osThreadId_t Angle_ringHandle;
const osThreadAttr_t Angle_ring_attributes = {
  .name = "Angle_ring",
  .stack_size = 128 * 4,
  .priority = (osPriority_t) osPriorityLow,
};
/* Definitions for L1_Mode */
osThreadId_t L1_ModeHandle;
const osThreadAttr_t L1_Mode_attributes = {
  .name = "L1_Mode",
  .stack_size = 128 * 4,
  .priority = (osPriority_t) osPriorityLow,
};
/* Definitions for Lift_Mode */
osThreadId_t Lift_ModeHandle;
const osThreadAttr_t Lift_Mode_attributes = {
  .name = "Lift_Mode",
  .stack_size = 128 * 4,
  .priority = (osPriority_t) osPriorityLow,
};
/* Definitions for One_Area */
osThreadId_t One_AreaHandle;
const osThreadAttr_t One_Area_attributes = {
  .name = "One_Area",
  .stack_size = 128 * 4,
  .priority = (osPriority_t) osPriorityLow,
};
/* Definitions for Two_Area */
osThreadId_t Two_AreaHandle;
const osThreadAttr_t Two_Area_attributes = {
  .name = "Two_Area",
  .stack_size = 128 * 4,
  .priority = (osPriority_t) osPriorityLow,
};
/* Definitions for Three_Area */
osThreadId_t Three_AreaHandle;
const osThreadAttr_t Three_Area_attributes = {
  .name = "Three_Area",
  .stack_size = 128 * 4,
  .priority = (osPriority_t) osPriorityLow,
};
/* Definitions for Mid360 */
osThreadId_t Mid360Handle;
const osThreadAttr_t Mid360_attributes = {
  .name = "Mid360",
  .stack_size = 128 * 4,
  .priority = (osPriority_t) osPriorityLow,
};
/* Definitions for Track_Mode */
osThreadId_t Track_ModeHandle;
const osThreadAttr_t Track_Mode_attributes = {
  .name = "Track_Mode",
  .stack_size = 128 * 4,
  .priority = (osPriority_t) osPriorityLow,
};

void StartDefaultTask(void *argument);
void Unitree_Function(void *argument);
void DM_Function(void *argument);
void DJI_Function(void *argument);
void Remote_Function(void *argument);
void DH_C_Function(void *argument);
void Remote_mode_function(void *argument);
void inverseKinematics_Function(void *argument);
void Angle_ring_Function(void *argument);
void L1_Mode_Function(void *argument);
void Lift_Mode_Function(void *argument);
void One_Area_Function(void *argument);
void Two_Area_Function(void *argument);
void Three_Area_Function(void *argument);
void Mid360_Function(void *argument);
void Track_Mode_Function(void *argument);

void MX_FREERTOS_Init(void); /* (MISRA C 2004 rule 8.1) */

void MX_FREERTOS_Init(void) {

  /* Create the thread(s) */
  /* creation of defaultTask */
  defaultTaskHandle = osThreadNew(StartDefaultTask, NULL, &defaultTask_attributes);

  /* creation of Unitree */
  UnitreeHandle = osThreadNew(Unitree_Function, NULL, &Unitree_attributes);

  /* creation of DM */
  DMHandle = osThreadNew(DM_Function, NULL, &DM_attributes);

  /* creation of DJI */
  DJIHandle = osThreadNew(DJI_Function, NULL, &DJI_attributes);

  /* creation of Remote */
  RemoteHandle = osThreadNew(Remote_Function, NULL, &Remote_attributes);

  /* creation of DH_C */
  DH_CHandle = osThreadNew(DH_C_Function, NULL, &DH_C_attributes);

  /* creation of Remote_mode */
  Remote_modeHandle = osThreadNew(Remote_mode_function, NULL, &Remote_mode_attributes);

  /* creation of inverseKinemati */
  inverseKinematiHandle = osThreadNew(inverseKinematics_Function, NULL, &inverseKinemati_attributes);

  /* creation of Angle_ring */
  Angle_ringHandle = osThreadNew(Angle_ring_Function, NULL, &Angle_ring_attributes);

  /* creation of L1_Mode */
  L1_ModeHandle = osThreadNew(L1_Mode_Function, NULL, &L1_Mode_attributes);

  /* creation of Lift_Mode */
  Lift_ModeHandle = osThreadNew(Lift_Mode_Function, NULL, &Lift_Mode_attributes);

  /* creation of One_Area */
  One_AreaHandle = osThreadNew(One_Area_Function, NULL, &One_Area_attributes);

  /* creation of Two_Area */
  Two_AreaHandle = osThreadNew(Two_Area_Function, NULL, &Two_Area_attributes);

  /* creation of Three_Area */
  Three_AreaHandle = osThreadNew(Three_Area_Function, NULL, &Three_Area_attributes);

  /* creation of Mid360 */
  Mid360Handle = osThreadNew(Mid360_Function, NULL, &Mid360_attributes);

  /* creation of Track_Mode */
  Track_ModeHandle = osThreadNew(Track_Mode_Function, NULL, &Track_Mode_attributes);

}

void StartDefaultTask(void *argument)
{
  /* USER CODE BEGIN StartDefaultTask */
  /* Infinite loop */
  for(;;)
  {
    if(visual_data.hmi_start != 1)
    {
      kfs_count_total_ready = 0U;
      R2_Extern.kfs_count_total = 0;
    }
    else if(kfs_count_total_ready == 0U)
    {
      R2_Extern.kfs_count_total = calc_kfs_count_total();
      kfs_count_total_ready = 1U;
    }

    set_yuntai_angle(R2_Extern.pitch_angle, R2_Extern.yaw_angle);
    meic_protocol_send_packet_dma(&huart10, R2_Extern.pitch_angle, R2_Extern.yaw_angle ,R2_Extern.work_mode);
    // set_yuntai_angle(10, -10);
    // meic_protocol_send_packet_dma(&huart10, 10,-10,2);
    // set_yuntai_angle(45, -10);
    // meic_protocol_send_packet_dma(&huart10, 45,-10,2);

    // if(guangdian == 1)
    // {
    //   R2_Extern.lingshi_flag = 10;
    // }
    // else
    // {
    //   R2_Extern.lingshi_flag = 0;
    // }

    osDelay(5);
  }
  /* USER CODE END StartDefaultTask */
}

void Unitree_Function(void *argument)
{
  /* USER CODE BEGIN Unitree_Function */
  /* Infinite loop */
  for(;;)
  {
    //小臂变为宇树电机了
    // unitree_cmd_create(&unitree_cmd[3], 3, 1, 10.7, 0.1, now_position.output_angle3, 0.0, 0.0);
    // unitree_communicate(3);
    // osDelay(10);

    unitree_cmd_create(&unitree_cmd[3], 3, 1, 0.0, 0.0, 0.0, 0.0, 0.0);
    unitree_communicate(3);
    osDelay(10);

    // if(R2_Extern.angle3 == 0)
    // {
    //   unitree_cmd_create(&unitree_cmd[3], 3, 1, 0.0, 0.0, 0.0, 0.0, 0.0);
    //   unitree_communicate(3);
    //   osDelay(10);
    // }
    // else
    // {
    //   unitree_cmd_create(&unitree_cmd[3], 3, 1, 10.7, 0.1, now_position.output_angle3, 0.0, 0.0);
    //   unitree_communicate(3);
    //   osDelay(10);
    // }

    //调试用
    osDelay(3);
  }
  /* USER CODE END Unitree_Function */
}

void DM_Function(void *argument)
{
  /* USER CODE BEGIN DM_Function */
  /* Infinite loop */
  for(;;)
  {
    DM_CAN_Enable_Motor(2);
    DM_CAN_Enable_Motor(3);
    DM_CAN_Enable_Motor(4);
    DM_CAN_Enable_Motor(5);
    DM_CAN_Enable_Motor(6);
    DM_CAN_Enable_Motor(7);

    DM_CAN_Send_PosVel_Mode(-(-R2_Extern.angle4  - unitree_pos[1] + dm4310_fb[1].position_deg) * 2.5,200,2);//上正
    DM_CAN_Send_PosVel_Mode(-R2_Extern.angle2,40,3);//上负    大臂电机改为8009了
      DM_CAN_Send_PosVel_Mode(R2_Extern.lift,1200,4);
      DM_CAN_Send_PosVel_Mode(R2_Extern.lift,1200,5);
    DM_CAN_Send_PosVel_Mode(R2_Extern.angle5,1200,6);//爪子
    DM_CAN_Send_PosVel_Mode(R2_Extern.angle1 * 1.625f,100,7);//云台：angle1为[-180, 180)相对角度

    //调试用
    // DM_CAN_Send_PosVel_Mode(0,0,2);
    // DM_CAN_Send_PosVel_Mode(0,0,3);
    // DM_CAN_Send_PosVel_Mode(0,0,4);
    // DM_CAN_Send_PosVel_Mode(0,0,5);
    // DM_CAN_Send_PosVel_Mode(0,0,6);
    // DM_CAN_Send_PosVel_Mode(0,0,7);
    osDelay(3);
  }
  /* USER CODE END DM_Function */
}

void DJI_Function(void *argument)
{
  /* USER CODE BEGIN DJI_Function */
  /* Infinite loop */
  for(;;)
  {
    FDCAN_cmd_chassis_fdcan1_0x200(pid_3508[0], pid_3508[1], pid_3508[2], pid_3508[3]);
    FDCAN_cmd_chassis_fdcan1_0x1FF(pid_3508[4], pid_3508[5], pid_3508[6], pid_3508[7]);
    FDCAN_cmd_chassis_fdcan3_0x200(pid_3508[8], pid_3508[9], pid_3508[10], pid_3508[11]);

    osDelay(3);
  }
  /* USER CODE END DJI_Function */
}

void Remote_Function(void *argument)
{
  /* USER CODE BEGIN Remote_Function */

  /* Infinite loop */
  for(;;)
  {
    // R2_Extern.lift_mood = 1;
    // R2_Extern.angle5 = 92;
    // R2_Extern.angle = rc_data.angle;
    // R2_Extern.speed = rc_data.distance *2;
    // R2_Extern.lingshi_flag = guangdian;

    // if(rc_data.btn_1 == 1)
    // {
    //   // fangkuang_open_1();
    //   qibeng_open();
    //   // chsaaic_front_up();
    //   // R2_Extern.angle2 += 1;
    //   // zhuazi_open();
    //   // R2_Extern.angle2 += 1;
    //   // fangkuang_open();
    //   // R2_Extern.lift_mood = 1;
    //   osDelay(200);
    // }
    // if(rc_data.btn_2 == 1)
    // {
    //   // fangkuang_close_1();
    //   qibeng_close();
    //   // chsaaic_front_down();
    //   // R2_Extern.angle2 -= 1;
    //   // zhuazi_close();
    //   // R2_Extern.angle2 -= 1;
    //   // fangkuang_close();
    //   // R2_Extern.lift_mood = 1;
    //   osDelay(200);
    //   // chsaaic_front_down();
    //   // R2_Extern.angle2 -= 1;
    //   // zhuazi_close();
    //   // R2_Extern.angle2 -= 1;
    //   // fangkuang_close();
    //   // put_kfs_3();
    //   osDelay(200);
    // }
    // if(rc_data.btn_3 == 1)
    // {
    //   fangkuang_open_2();
    //   // R2_Extern.angle3 += 1;
    //   // chsaaic_behind_up();
    //   // R2_Extern.angle3 += 1;
    //   // put_kfs_1();
    //   osDelay(200);
    // }
    // if(rc_data.btn_4 == 1)
    // {
    //   fangkuang_close_2();
    //   // R2_Extern.angle3 -= 1;
    //   // chsaaic_behind_down();
    //   // R2_Extern.angle3 -= 1;
    //   // put_kfs_2();
    //   osDelay(200);
    // }

    // if(R2_Extern.get_init == 0)
    // {
    //   // R2_Extern.angle2 = angle_2;
    //   // R2_Extern.angle3 = angle_3;
    //   R2_Extern.angle2 = 30;
    //   R2_Extern.angle3 = 45;
    //   R2_Extern.angle4 = 0;
    //   // R2_Extern.lift_mood = 1;
    //   // osDelay(1000);
    //   // chsaaic_behind_up();
    //   // chsaaic_front_up();
    //   // R2_Extern.angle2 = 145;
    //   // R2_Extern.angle3 = 80;
    //   // R2_Extern.angle4 = 0;
    //   if(unitree_pos[1]>= R2_Extern.angle3 - 5 && unitree_pos[1] <= R2_Extern.angle3 + 5 && dm4310_fb[1].position_deg >= R2_Extern.angle2 - 5 && dm4310_fb[1].position_deg <= R2_Extern.angle2 + 5)
    //   {
    //     R2_Extern.get_init = 1;
    //   }
    // }

    // if(rc_data.btn_1 == 1)
    // {
    //   R2_Extern.angle_balance_target += 1;
    //   // chsaaic_behind_up();
    //   // fangkuang_open();
    //   // osDelay(50);
    // }
    // if(rc_data.btn_2 == 1)
    // {
    //   R2_Extern.angle_balance_target -= 1;
    //   // chsaaic_behind_down();
    //   // fangkuang_close();
    //   // osDelay(50);
    // }
    // if(rc_data.btn_3 == 1)
    // {
    //   // fangkuang_open();
    //   R2_Extern.Area2_flag = 1;
    //   // R2_Extern.angle5 = 95;
    //   // chsaaic_front_up();
    // }
    // if(rc_data.btn_4 == 1)
    // {
    //   // fangkuang_close();
    //   R2_Extern.Area2_flag = 5;
    //   // R2_Extern.angle5 = 130;
    //   // chsaaic_front_down();
    // }

    //     if(rc_data.btn_1 == 1 && rc_data.btn_2 == 1)
    // {
    //   // R2_Extern.angle5 = -80;
    //   // osDelay(100);
    //   chsaaic_behind_down();
    //   osDelay(200);
    // }
    // else if(rc_data.btn_1 == 1 && rc_data.btn_3 == 1)
    // {
    //   // R2_Extern.angle5 = 0;
    //   // osDelay(100);
    //   chsaaic_behind_up();
    //   osDelay(200);
    // }
    // else if(rc_data.btn_2 == 1 && rc_data.btn_3 == 1)
    // {
    //   // grap_on();
    //   // osDelay(100);
    //   chsaaic_front_down();
    //   osDelay(200);
    // }
    // else if(rc_data.btn_2 == 1 && rc_data.btn_4 == 1)
    // {
    //   // grap_off();
    //   // osDelay(100);
    //   chsaaic_front_up();
    //   osDelay(200);
    // }
    // else if(rc_data.btn_3 == 1 && rc_data.btn_4 == 1)
    // {
    //   R2_Extern.lift_mood = 1;
    //   osDelay(200);
    // }

//       switch (R2_Extern.Area2_flag)
//       {
//       case 0:
//           // R2_Extern.angle = 0;
//           // R2_Extern.speed = 0;
//           // R2_Extern.angle_balance_target = 0;
//         break;

//       case 1:
//           if(R2_Extern.lift_mood == 0)
//           {
//             R2_Extern.lift_mood = 1;
//             osDelay(2000);
//           }
//           R2_Extern.angle = 0;
//           R2_Extern.speed = 0.3;
//           if(Area_Flag.qian_dis == 1 && R2_Extern.lift_mood == 1)
//           {
//               R2_Extern.angle = 0;
//               R2_Extern.speed = 0;
//               R2_Extern.Area2_flag = 2;
//           }
//         break;

//       case 2:
//           if(R2_Extern.chsaaic_behind_flag == 0)
//           {
//             chsaaic_behind_up();
//             R2_Extern.chsaaic_behind_flag = 1;
//             osDelay(500);
//           }
//           R2_Extern.lift_mood = 2;
//           osDelay(2000);
//           R2_Extern.Area2_flag = 3;
//         break;

//       case 3:
//           now_mood.mood = 1;
//           R2_Extern.angle = 0;
//           R2_Extern.speed = 0.3;
//           if(Area_Flag.hou_dis == 1)
//           {
//             now_mood.mood = 0;
//             R2_Extern.angle = 0;
//             R2_Extern.speed = 0;
//             chsaaic_behind_down();
//             R2_Extern.lift_mood = 0;
//             R2_Extern.chsaaic_behind_flag = 0;
//             osDelay(1000);
//             R2_Extern.Area2_flag = 4;
//           }
//         break;

//       case 4:
//           R2_Extern.angle = 0;
//           R2_Extern.speed = 0.3;
//           osDelay(500);
//           R2_Extern.Area2_flag = 0;
//           R2_Extern.complete_taijie_flag = 1;

//         break;
// //上台阶1到4

//       case 5:
//           if(R2_Extern.lift_mood == 0)
//           {
//             R2_Extern.lift_mood = 1;
//             osDelay(1000);
//           }
//           if(R2_Extern.chack_yaw_flag == 1)
//           {
//             R2_Extern.angle = 0;
//             R2_Extern.speed = 0.2;
//           }
//           else
//           {
//             R2_Extern.angle = 0;
//             R2_Extern.speed = 0;
//           }

//           if(Area_Flag.qian_dis == 2 && R2_Extern.lift_mood == 1)
//           {
//               R2_Extern.angle = 0;
//               R2_Extern.speed = 0;
//               R2_Extern.Area2_flag = 6;
//           }
//         break;

//       case 6:
//           if(R2_Extern.lift_mood == 1)
//           {
//             R2_Extern.lift_mood = 2;
//             chsaaic_front_up();
//             osDelay(2500);
//           }
//           R2_Extern.angle = 0;
//           R2_Extern.speed = 0.2;
//           now_mood.mood = 1;

//           if(Area_Flag.hou_dis == 0 && R2_Extern.lift_mood == 2)
//           {
//             now_mood.mood = 0;
//             R2_Extern.angle = 0;
//             R2_Extern.speed = 0;
//             osDelay(100);
//             R2_Extern.Area2_flag = 7;
//           }
//       break;

//       case 7:
//             R2_Extern.lift_mood = 1;
//             osDelay(2000);
//             chsaaic_front_down();
//             R2_Extern.Area2_flag = 8;

//       break;

//       case 8:
//           R2_Extern.angle = 0;
//           R2_Extern.speed = 0.3;
//           osDelay(1000);
//           R2_Extern.lift_mood = 0;
//           R2_Extern.Area2_flag = 0;
//           R2_Extern.complete_taijie_flag = 1;
//           if(R2_Extern.complete_erqu_flag == 1)
//           {
//             R2_Extern.start_sanqugoon_flag = 1;
//             R2_Extern.bool_meilin_flag = 1;
//           }
//       break;
// //下台阶5到8

//       default:
//         break;
//     }

    // if(R2_Extern.lingshi_flag == 0)
    // {
    //   osDelay(2000);
    //   zhuazi_mode_1_5();
    //   osDelay(1000);
    //   zhuazi_mode_2();
    //   osDelay(1000);
    //   zhuazi_mode_3();
    //   osDelay(1000);
    //   zhuazi_mode_4();
    //   osDelay(1000);
    //   zhuazi_mode_1_5();
    //   osDelay(2000);
    //   zhuazi_mode_6();
    //   osDelay(1000);
    //   zhuazi_mode_7();
    //   osDelay(1000);
    //   R2_Extern.lingshi_flag = 1;
    // }

    // chassic_control(R2_Extern.angle,R2_Extern.speed,R2_Extern.span+(-R2_Extern.error_balance*200));

    osDelay(5);
  }
  /* USER CODE END Remote_Function */
}

void DH_C_Function(void *argument)
{
  /* USER CODE BEGIN DH_C_Function */
  /* Infinite loop */
  for(;;)
  {
    computeDHTransform(dm4310_fb[5].position_deg, dm4310_fb[1].position_deg , unitree_pos[1], &R2_Extern.x_t, &R2_Extern.y_t, &R2_Extern.z_t);
    // inverseKinematics(x,y,z,&angle1,&angle2,&angle3);
    osDelay(5);
  }
  /* USER CODE END DH_C_Function */
}

void Remote_mode_function(void *argument)
{
  /* USER CODE BEGIN Remote_mode_function */
  /* Infinite loop */
  for(;;)
  {
    if(L1_Sensor1.distance_mm <= 190)
    {
      Area_Flag.qian_dis = 1;//低
    }
    else if(L1_Sensor1.distance_mm >= 450)
    {
      Area_Flag.qian_dis = 2;//高
    }
    else
    {
      Area_Flag.qian_dis = 0;
    }

    if(L1_Sensor2.distance_mm <= 280)
    {
      Area_Flag.hou_dis = 1;//低
    }
    else if(L1_Sensor2.distance_mm >= 550)
    {
      Area_Flag.hou_dis = 2;//高
    }
    else
    {
      Area_Flag.hou_dis = 0;
    }

    //检测姿态
    if(fabsf(R2_Extern.error_balance) < 2.0f)
    {
      R2_Extern.chack_yaw_flag = 1;
    }
    else
    {
      R2_Extern.chack_yaw_flag = 0;
    }

    //检测定位
    uint8_t cell = visual_data.meilin_points[R2_Extern.meilin_count_flag].cell;

    if(cell >= 1 && cell <= 12)
    {
      check_dingwei(visual_data.x_map, visual_data.y_map, cell - 1);
    }

    //是否看到矿
    if(visual_data.bool_getKFS == 1)
    {
      R2_Extern.KFS_Get_flag = 1;
    }
    else
    {
      R2_Extern.KFS_Get_flag = 0;
    }

    //云台
    if(abs(R2_Extern.angle1 - dm4310_fb[5].position_deg) < 5)
    {
      R2_Extern.check_angle1_flag = 1;
    }
    else
    {
      R2_Extern.check_angle1_flag = 0;
    }

    //大臂
    if(abs(R2_Extern.angle2 - dm4310_fb[1].position_deg) < 5)
    {
      R2_Extern.check_angle2_flag = 1;
    }
    else
    {
      R2_Extern.check_angle2_flag = 0;
    }

    //小臂
    if(abs(R2_Extern.angle3 - unitree_pos[1]) < 5)
    {
      R2_Extern.check_angle3_flag = 1;
    }
    else
    {
      R2_Extern.check_angle3_flag = 0;
    }

    //手腕
    if(abs(R2_Extern.angle4 - dm4310_fb[0].position_deg) < 5)
    {
      R2_Extern.check_angle4_flag = 1;
    }
    else
    {
      R2_Extern.check_angle4_flag = 0;
    }

    //爪子
    if(abs(R2_Extern.angle5 + dm4310_fb[4].position_deg) < 5)
    {
      R2_Extern.check_angle5_flag = 1;
    }
    else
    {
      R2_Extern.check_angle5_flag = 0;
    }

    osDelay(1);
  }
  /* USER CODE END Remote_mode_function */
}

void inverseKinematics_Function(void *argument)
{
  /* USER CODE BEGIN inverseKinematics_Function */
  /* Infinite loop */
  for(;;)
  {
    arm_unitree_planning_update(R2_Extern.angle1, R2_Extern.angle3);
    osDelay(25);
  }
  /* USER CODE END inverseKinematics_Function */
}

void Angle_ring_Function(void *argument)
{
  /* USER CODE BEGIN Angle_ring_Function */
  static float prev_hipnuc_angle_z = 0.0f;
  static float total_wrap_angle_z = 0.0f;
  static float plan_start_angle = 0.0f;
  static float plan_delta_angle = 0.0f;
  static float plan_target_angle = 0.0f;
  static uint32_t plan_start_tick = 0U;
  static float plan_duration_s = 0.0f;
  static uint8_t plan_active = 0U;
  /* Infinite loop */
  for(;;)
  {
    float current_angle = ops.HIPNUCAngleZ;
    float delta = current_angle - prev_hipnuc_angle_z;
    if (delta > 180.0f) {
        total_wrap_angle_z -= 360.0f;
    } else if (delta < -180.0f) {
        total_wrap_angle_z += 360.0f;
    }
    prev_hipnuc_angle_z = current_angle;
    float continuous_angle = current_angle + total_wrap_angle_z;

    float target_diff = angle_ring_normalize_deg(R2_Extern.angle_balance_target - plan_target_angle);
    if(plan_active == 0U || angle_ring_absf(target_diff) > ANGLE_RING_TARGET_EPSILON_DEG)
    {
      plan_start_angle = R2_Extern.angle_balance;
      plan_delta_angle = angle_ring_normalize_deg(R2_Extern.angle_balance_target - plan_start_angle);
      plan_target_angle = plan_start_angle + plan_delta_angle;
      plan_start_tick = HAL_GetTick();

      float distance = angle_ring_absf(plan_delta_angle);
      if(distance <= ANGLE_RING_TARGET_EPSILON_DEG)
      {
        R2_Extern.angle_balance = R2_Extern.angle_balance_target;
        plan_duration_s = 0.0f;
        plan_active = 0U;
      }
      else
      {
        plan_duration_s = 1.875f * distance / ANGLE_RING_MAX_SPEED_DPS;
        if(plan_duration_s < ANGLE_RING_MIN_DURATION_S)
        {
          plan_duration_s = ANGLE_RING_MIN_DURATION_S;
        }
        plan_active = 1U;
      }
    }

    if(plan_active != 0U)
    {
      float elapsed_s = (float)(HAL_GetTick() - plan_start_tick) * 0.001f;
      if(elapsed_s >= plan_duration_s)
      {
        R2_Extern.angle_balance = plan_target_angle;
        plan_active = 0U;
      }
      else
      {
        float u = elapsed_s / plan_duration_s;
        float u2 = u * u;
        float u3 = u2 * u;
        float smooth = (10.0f * u3) - (15.0f * u2 * u2) + (6.0f * u3 * u2);
        R2_Extern.angle_balance = plan_start_angle + plan_delta_angle * smooth;
      }
    }

    R2_Extern.angle_balance = angle_ring_normalize_deg(R2_Extern.angle_balance);

    // 将角度误差归一化到 [-180, 180]，确保以劣弧(最短路径)方向旋转
    R2_Extern.error_balance = fmodf(R2_Extern.angle_balance - continuous_angle, 360.0f);
    if (R2_Extern.error_balance > 180.0f) R2_Extern.error_balance -= 360.0f;
    if (R2_Extern.error_balance < -180.0f) R2_Extern.error_balance += 360.0f;
    osDelay(5);
  }
  /* USER CODE END Angle_ring_Function */
}

void L1_Mode_Function(void *argument)
{
  /* USER CODE BEGIN L1_Mode_Function */
  /* Infinite loop */
  for(;;)
  {
    L1_Control(&L1_Sensor1, L1_MODE_FAST);
    L1_Control(&L1_Sensor2, L1_MODE_FAST);
    osDelay(5);
  }
  /* USER CODE END L1_Mode_Function */
}

void Lift_Mode_Function(void *argument)
{
  /* USER CODE BEGIN Lift_Mode_Function */
  /* Infinite loop */
  for(;;)
  {
    if(R2_Extern.lift_mood == 1)
    {
      // while(R2_Extern.lift <= 400)
      // {
      //   R2_Extern.lift += 1;
      //   osDelay(1);
      // }
      // R2_Extern.lift = 470;
      R2_Extern.lift = 485;
    }
    else if(R2_Extern.lift_mood == 0)
    {
      // while(R2_Extern.lift >= 20)
      // {
      //   R2_Extern.lift -= 1;
      //   osDelay(1);
      // }
      // if(R2_Extern.lift <= 20)
      // {
      //   R2_Extern.lift = 20;
      // }
      R2_Extern.lift = 100;
    }
    else if (R2_Extern.lift_mood == 2)
    {
      R2_Extern.lift = 0;
    }
    osDelay(5);
  }
  /* USER CODE END Lift_Mode_Function */
}

void One_Area_Function(void *argument)
{
  /* USER CODE BEGIN One_Area_Function */
  /* Infinite loop */
  for(;;)
  {
    if(visual_data.hmi_start != 1)
    {
      R2_Extern.angle = 0;
      R2_Extern.speed = 0;
      osDelay(5);
      continue;
    }

    if(visual_data.workl_mode == 1 && R2_Extern.Area1_1_flag == 1)
    {
      const float (*area_1_dt35)[2] = (R2_Extern.Track_flag == 0) ? area_1_dt35_red : area_1_dt35_blue;

      switch(R2_Extern.Area1_flag)
      {
        case 0:
        // R2_Extern.Area1_id = visual_data.targetid;
        // R2_Extern.Area1_id = 1;
        if(R2_Extern.Area1_qukuang_flag == 0)
        {
          if(R2_Extern.Track_flag == 0)
          {
            R2_Extern.Area1_id = 2;
          }
          else
          {
            R2_Extern.Area1_id = 6;
          }
          R2_Extern.Area1_qukuang_flag = 1;
        }

        if(R2_Extern.Area1_id == 0)
        {
          break;
        }

        if(R2_Extern.Track_flag == 0)
        {
          R2_Extern.angle_balance_target = -90;
        }
        else if(R2_Extern.Track_flag == 1)
        {
          R2_Extern.angle_balance_target = 90;
        }
        if(R2_Extern.chack_yaw_flag == 1)
        {

          R2_Extern.Area1_flag = 1;
        }
        break;

        case 1:
          R2_Extern.angle = 0;
          R2_Extern.speed = 0;
          R2_Extern.angle5 = 140;

          if(R2_Extern.check_angle5_flag == 1)
          {
            R2_Extern.Area1_flag = 2;
          }
        break;

        case 2:
          zhuazi_open();
          quzhua(area_1_dt35[R2_Extern.Area1_id-1][0], area_1_dt35[R2_Extern.Area1_id-1][1]);
          if(R2_Extern.Area1_2_flag == 1)
          {
            R2_Extern.Area1_flag = 3;
          }
        break;

        case 3:
        R2_Extern.angle5 = 90;
        osDelay(500);

          R2_Extern.Area1_flag = 4;
        break;

        case 4:
            zhuazi_close();
            osDelay(200);
            R2_Extern.angle5 = 140;
            R2_Extern.Area1_flag = 5;
        break;

        case 5:
          if(R2_Extern.check_angle5_flag == 1)
          {

            if(guangdian == 0)
            {
              osDelay(200);
              if(guangdian == 0)
              {
                R2_Extern.Area1_flag = 6;
              }
            }
            else
            {
              if(R2_Extern.Track_flag == 0)
              {
                R2_Extern.Area1_id += 1;
                R2_Extern.Area1_flag = 2;
              }
              else
              {
                R2_Extern.Area1_id -= 1;
                R2_Extern.Area1_flag = 2;
              }
            }

          }
        break;

        case 6:

          if(R2_Extern.Track_flag == 0)
          {
            quzhua(area_1_dt35[1][0]+100, area_1_dt35[2][1]+400);
          }
          else
          {
            quzhua(area_1_dt35[4][0]+100, area_1_dt35[5][1]+400);
          }

          if(R2_Extern.Area1_2_flag == 1)
          {
            R2_Extern.angle = 0;
            R2_Extern.speed = 0;
            R2_Extern.Area1_flag = 7;
          }
        break;

        case 7:
          R2_Extern.angle5 = 0;
          if(R2_Extern.check_angle5_flag == 1)
          {
            R2_Extern.Area1_flag = 8;
          }
        break;

        case 8:
          // R2_Extern.Area1_dx = -(float)(visual_data.dx) * 1.0f;
          // back_keep_x(area_1_dt35[3][0]+200,0,0);
          // back_keep_y(area_1_dt35[3][1]+600,0,0);
          quzhua_dui(area_1_dt35[1][1] + 600 , -R2_Extern.Area1_dx*1.0);
          if(visual_data.usblightid == 0)//重新拿武器
          {
            R2_Extern.angle5 = 140;
            if(R2_Extern.Track_flag == 0)
              {
                R2_Extern.Area1_id += 1;
                R2_Extern.Area1_flag = 2;
              }
              else
              {
                R2_Extern.Area1_id -= 1;
                R2_Extern.Area1_flag = 2;
              }

          }
          if(visual_data.usblightid == 1)//松
          {
            zhuazi_open();
          }
          if(visual_data.usblightid == 2)//进2区
          {
            R2_Extern.angle_balance_target = 0;
            R2_Extern.Area1_flag = 9;
          }
        break;

        case 9:

        break;
        default:
        break;
      }
    }
    osDelay(1);
  }
  /* USER CODE END One_Area_Function */
}

void Two_Area_Function(void *argument)
{
  /* USER CODE BEGIN Two_Area_Function */
  /* Infinite loop */
  for(;;)
  {
    if(visual_data.hmi_start != 1)
    {
      R2_Extern.angle = 0;
      R2_Extern.speed = 0;
      osDelay(5);
      continue;
    }

    const float (*area_2_special)[2] = (R2_Extern.Track_flag == 0) ? area_2_special_red : area_2_special_blue;

    if(visual_data.workl_mode == 2 && R2_Extern.check_1_flag == 0)
    {
        chassic_control_auto(&chassic_data, visual_data.x_map, visual_data.y_map, area_2_special[1][0], area_2_special[1][1], 1.0);
        R2_Extern.angle = chassic_data.angle;
        R2_Extern.speed = chassic_data.distance;
        check_dingwei_2(visual_data.x_map, visual_data.y_map, area_2_special[1][0], area_2_special[1][1]);
        if(R2_Extern.bool_check_1_flag == 1)
        {
            R2_Extern.angle = 0;
            R2_Extern.speed = 0;
            R2_Extern.check_1_flag = 1;
        }
    }

    if(visual_data.workl_mode == 2 && R2_Extern.check_1_flag == 1 && R2_Extern.bool_meilin_flag == 0)
    {

          if(R2_Extern.complete_flag == 0)
          {
            if (R2_Extern.meilin_count_flag < visual_data.meilin_count)
            {
              MeilinPointCmd current_point = visual_data.meilin_points[R2_Extern.meilin_count_flag];
              R2_Extern.KFS_Grap_flag = current_point.has_true_kfs;//取矿，暂时注释
              R2_Extern.qukuang_mode_flag = current_point.vertical_s;
              if(R2_Extern.KFS_Grap_flag == 1)
              {
                R2_Extern.bool_KFS_flag = 1;
              }
              else
              {
                R2_Extern.bool_KFS_flag = 0;
              }

              if (current_point.cell == 0)
              {
                  R2_Extern.meilin_count_flag++;
                  continue;
              }

              if (current_point.cell > 15)
              {
                  R2_Extern.angle = 0;
                  R2_Extern.speed = 0;
                  R2_Extern.meilin_count_flag++;
                  continue;
              }

              switch(current_point.horizontal_s)
              {
                case 1: R2_Extern.angle_balance_target = 90; break;
                case 2: R2_Extern.angle_balance_target = -90;  break;
                case 3: R2_Extern.angle_balance_target = 0;   break;
                case 4: R2_Extern.angle_balance_target = 180; break;
                default: break;
              }

              if (current_point.cell >= 13 && current_point.cell <= 15)
              {
                  // R2_Extern.bool_KFS_flag = 1;
                  // R2_Extern.KFS_Grap_flag = 1;
                  if (R2_Extern.chack_yaw_flag == 1)
                  {
                      R2_Extern.Area2_flag = current_point.cell;
                      R2_Extern.complete_flag = 1;
                  }
              }
              else if (R2_Extern.chack_yaw_flag == 1)
              {
                  switch(current_point.vertical_s)
                  {
                      case 5:
                      R2_Extern.Area2_flag = 1;
                      R2_Extern.pitch_angle = 0;
                      break;
                      case 6:
                      R2_Extern.Area2_flag = 5;
                      R2_Extern.pitch_angle = -10;
                      break;
                      default: break;
                  }

                  R2_Extern.complete_flag = 1;
              }
            }

          }

          if(R2_Extern.complete_taijie_flag == 1 && R2_Extern.complete_dingwei_flag == 1)
          {
            R2_Extern.complete_flag = 0;
            R2_Extern.complete_taijie_flag = 0;
            R2_Extern.complete_dingwei_flag = 0;
            R2_Extern.bool_check_1_flag = 0;
            R2_Extern.meilin_count_flag++;
            if(R2_Extern.meilin_count_flag == visual_data.meilin_count)
            {
              if(R2_Extern.complete_erqu_flag == 0)
                {
                  R2_Extern.complete_erqu_flag = 1;
                  R2_Extern.angle_balance_target = 0;
                  R2_Extern.Area2_flag = 5;
                }
            }
          }

      if(R2_Extern.bool_KFS_flag == 0)
      {
        switch (R2_Extern.Area2_flag)
        {
        case 0:
            R2_Extern.angle = 0;
            R2_Extern.speed = 0;
            R2_Extern.angle_balance_target = 0;

            if(R2_Extern.chack_yaw_flag == 1)
            {
              R2_Extern.car_flag = 1;
            }
          break;

        case 1:

            R2_Extern.car_flag = 0;
            // R2_Extern.lift_mood = 1;
            if(R2_Extern.lift_mood == 0)
            {
              R2_Extern.lift_mood = 1;
              osDelay(800);
            }
            if(R2_Extern.chack_yaw_flag == 1 && R2_Extern.KFS_Get_flag == 0)
            {
              R2_Extern.angle = 0;
              R2_Extern.speed = 0.5;
            }
            else
            {
              R2_Extern.angle = 0;
              R2_Extern.speed = 0;
            }

            if(Area_Flag.qian_dis == 1 && R2_Extern.lift_mood == 1)
            {
                R2_Extern.angle = 0;
                R2_Extern.speed = 0;
                R2_Extern.Area2_flag = 2;
            }
          break;

        case 2:
            if(R2_Extern.chsaaic_behind_flag == 0)
            {
              chsaaic_behind_up();
              R2_Extern.chsaaic_behind_flag = 1;
              osDelay(500);
            }
            R2_Extern.lift_mood = 2;
            osDelay(500);
            R2_Extern.Area2_flag = 23;
          break;

        case 23:
            now_mood.mood = 2;
            R2_Extern.angle = 0;
            R2_Extern.speed = 1.0;
            osDelay(500);
            R2_Extern.Area2_flag = 3;

        case 3:
            now_mood.mood = 1;
            R2_Extern.angle = 0;
            R2_Extern.speed = 0.3;
            if(Area_Flag.hou_dis == 1)
            {
              now_mood.mood = 0;
              R2_Extern.angle = 0;
              R2_Extern.speed = 0;
              chsaaic_behind_down();
              // R2_Extern.lift_mood = 0;
              R2_Extern.lift_mood = 1;
              R2_Extern.chsaaic_behind_flag = 0;
              osDelay(500);
              R2_Extern.Area2_flag = 4;
            }
          break;

        case 4:
            R2_Extern.angle = 0;
            R2_Extern.speed = 0.3;
            osDelay(500);
            // R2_Extern.lift_mood = 1;
            R2_Extern.Area2_flag = 0;
            R2_Extern.complete_taijie_flag = 1;

          break;
//上台阶1到4

        case 5:
            R2_Extern.car_flag = 0;
            if(R2_Extern.lift_mood == 0)
            {
              R2_Extern.angle = 0;
              R2_Extern.speed = 0;
              R2_Extern.lift_mood = 1;
              osDelay(1000);
            }
            if(R2_Extern.chack_yaw_flag == 1 && R2_Extern.KFS_Get_flag == 0)
            {
              R2_Extern.angle = 0;
              R2_Extern.speed = 0.2;
            }
            else
            {
              R2_Extern.angle = 0;
              R2_Extern.speed = 0;
            }

            if(Area_Flag.qian_dis == 2 && R2_Extern.lift_mood == 1)
            {
                R2_Extern.angle = 0;
                R2_Extern.speed = 0;
                R2_Extern.Area2_flag = 6;
            }
          break;

        case 6:
            if(R2_Extern.lift_mood == 1)
            {
              R2_Extern.lift_mood = 2;
              chsaaic_front_up();
              osDelay(1000);
            }
            R2_Extern.angle = 0;
            R2_Extern.speed = 0.2;
            now_mood.mood = 1;

            if(Area_Flag.hou_dis == 0 && R2_Extern.lift_mood == 2)
            {
              now_mood.mood = 0;
              R2_Extern.angle = 0;
              R2_Extern.speed = 0;
              osDelay(100);
              R2_Extern.Area2_flag = 7;
            }
        break;

        case 7:
              R2_Extern.lift_mood = 1;
              osDelay(1000);
              chsaaic_front_down();
              R2_Extern.Area2_flag = 8;

        break;

        case 8:
            R2_Extern.angle = 0;
            R2_Extern.speed = 0.2;
            osDelay(1000);
            // R2_Extern.lift_mood = 1;
            R2_Extern.Area2_flag = 0;
            R2_Extern.complete_taijie_flag = 1;
            if(R2_Extern.complete_erqu_flag == 1)
            {
              // R2_Extern.angle_balance_target = 0;
              R2_Extern.start_sanqugoon_flag = 1;
              R2_Extern.lift_mood = 0;
              R2_Extern.bool_meilin_flag = 1;
              R2_Extern.sanqugoon_step = 0;
            }
        break;

        case 13:
            chassic_control_auto(&chassic_data, visual_data.x_map, visual_data.y_map, area_2_special[0][0], area_2_special[0][1] , 1.0);
            R2_Extern.angle = chassic_data.angle;
            R2_Extern.speed = chassic_data.distance;
            check_dingwei_2(visual_data.x_map, visual_data.y_map, area_2_special[0][0], area_2_special[0][1]);
            R2_Extern.lift_mood = 1;
            if(R2_Extern.bool_check_1_flag == 1)
            {
              R2_Extern.angle = 0;
              R2_Extern.speed = 0;
              R2_Extern.lift_mood = 1;
              R2_Extern.qukuang_mode_flag = 5;
              R2_Extern.KFS_Grap_flag = 1;
              R2_Extern.bool_KFS_flag = 1;
              R2_Extern.KFS_status_flag = 1;
              R2_Extern.Area2_flag = 16;
            }
          break;

        case 14:

              // R2_Extern.complete_dingwei_flag = 1;
              // R2_Extern.complete_taijie_flag = 1;//这两行是为了让点遍历推进
              chassic_control_auto(&chassic_data, visual_data.x_map, visual_data.y_map, area_2_special[1][0], area_2_special[1][1], 1.0);
              R2_Extern.angle = chassic_data.angle;
              R2_Extern.speed = chassic_data.distance;
              check_dingwei_2(visual_data.x_map, visual_data.y_map, area_2_special[1][0], area_2_special[1][1]);
              R2_Extern.lift_mood = 0;
              if(R2_Extern.bool_check_1_flag == 1)
              {
                R2_Extern.Area2_flag = 0;
                R2_Extern.complete_dingwei_flag = 1;
                R2_Extern.complete_taijie_flag = 1;
              }
              // R2_Extern.Area2_flag = 0;

          break;

        case 15:
            chassic_control_auto(&chassic_data, visual_data.x_map, visual_data.y_map, area_2_special[2][0], area_2_special[2][1] , 1.0);
            R2_Extern.angle = chassic_data.angle;
            R2_Extern.speed = chassic_data.distance;
            check_dingwei_2(visual_data.x_map, visual_data.y_map, area_2_special[2][0], area_2_special[2][1]);
            R2_Extern.lift_mood = 1;
            if(R2_Extern.bool_check_1_flag == 1)
            {
              R2_Extern.angle = 0;
              R2_Extern.speed = 0;
              R2_Extern.qukuang_mode_flag = 5;
              R2_Extern.lift_mood = 1;
              R2_Extern.KFS_Grap_flag = 1;
              R2_Extern.bool_KFS_flag = 1;
              R2_Extern.KFS_status_flag = 1;
              R2_Extern.Area2_flag = 16;
            }
          break;

        case 16:
          if(R2_Extern.special_flag == 1)
          {
            R2_Extern.Area2_flag = 14;
          }
          break;

        default:
          break;
      }
    }

  }

  if(visual_data.workl_mode == 2 && R2_Extern.KFS_Grap_flag == 1 && R2_Extern.bool_KFS_flag == 1)
  {
    int x;
    if(R2_Extern.qukuang_mode_flag == 5)
    {
      x = 550;
    }
    else if(R2_Extern.qukuang_mode_flag == 6)
    {
      x = 630;
    }
      switch(R2_Extern.KFS_status_flag)
      {
        case 0:
          if(R2_Extern.Area2_flag == 13 || R2_Extern.Area2_flag == 15 || R2_Extern.Area2_flag == 16)
          {
            R2_Extern.lift_mood = 1;
          }
          else
          {
            R2_Extern.lift_mood = 0;
          }

          if(R2_Extern.KFS_Get_flag == 1 && visual_data.xyz_in_base[0] <= x && R2_Extern.chack_yaw_flag == 1)//上取下650 下取上570
          {
            if(R2_Extern.kfs_count_total == 3 && R2_Extern.kfs_count == 0)
            {
              R2_Extern.angle = 0;
              R2_Extern.speed = 0;
              R2_Extern.KFS_status_flag = 10;
            }
            else
            {
              R2_Extern.angle = 0;
              R2_Extern.speed = 0;
              // R2_Extern.lift_mood = 0;//降下去
              // R2_Extern.angle4 = 90;
              // R2_Extern.lift_mood = 0;
              // R2_Extern.lift_mood = 1;
              R2_Extern.KFS_status_flag = 1;
              osDelay(200);
            }
          }
          else
          {
            if(R2_Extern.chack_yaw_flag == 1)
            {
              R2_Extern.speed = 0.2;
            }
            else
            {
              R2_Extern.speed = 0;
            }
          }

        break;

        case 1:
        if(R2_Extern.KFS_Get_flag == 1 && visual_data.xyz_in_base[0] <= x)
        {
          qibeng_open();
          up_stair();
          if(unitree_pos[1]>= angle_3 - 10 && unitree_pos[1] <= angle_3 + 10 && dm4310_fb[1].position_deg >= angle_2 - 10 && dm4310_fb[1].position_deg <= angle_2 + 10)
          {
            // osDelay(1000);
            R2_Extern.KFS_status_flag = 3;
          }
          R2_Extern.KFS_status_flag = 3;
        }
        else
        {
          R2_Extern.speed = 0.2;
        }
        break;

        case 3:
        {
          qukuang_move_y(400);//上抓下400 下抓上400

          if(visual_data.kfs_x >= 380 && visual_data.kfs_x <= 420)//这也要改
          {
            R2_Extern.KFS_status_flag = 33;
          }
        }
        break;

        case 33:
            if(R2_Extern.qukuang_mode_flag == 5)
            {
              R2_Extern.angle1 = 0;
              // R2_Extern.angle2 = 120;
              R2_Extern.angle2 = 115;
              R2_Extern.angle3 = 120;//下取上
            }
            else if (R2_Extern.qukuang_mode_flag == 6)
            {
              R2_Extern.angle1 = 0;
              R2_Extern.angle2 = 110;
              // R2_Extern.angle2 = 120;
              R2_Extern.angle3 = 75;//上取下
            }

            // R2_Extern.angle4 = 80;

            // if(unitree_pos[1]>= R2_Extern.angle3 - 10 && unitree_pos[1] <= R2_Extern.angle3 + 10 && dm4310_fb[1].position_deg >= R2_Extern.angle2 - 10 && dm4310_fb[1].position_deg <= R2_Extern.angle2 + 10)
            // {
            //   // osDelay(500);
            //   // R2_Extern.angle2 = 100;
            //   // osDelay(500);
            //   // R2_Extern.angle4 = 0;
            //   R2_Extern.KFS_status_flag = 4;
            // }

            if(unitree_pos[1]>= R2_Extern.angle3 - 90 && unitree_pos[1] <= R2_Extern.angle3 + 90 && dm4310_fb[1].position_deg >= R2_Extern.angle2 - 90 && dm4310_fb[1].position_deg <= R2_Extern.angle2 + 90)
            {
                if(R2_Extern.kfs_count == 0 && R2_Extern.kfs_count_total != 3)
                {
                  R2_Extern.angle4 = 80;
                }
                else if(R2_Extern.kfs_count == 1 && R2_Extern.kfs_count_total == 3)
                {
                  R2_Extern.angle4 = 80;
                }
                else
                {
                  R2_Extern.angle4 =-20;
                }
                if(unitree_pos[1]>= R2_Extern.angle3 - 5 && unitree_pos[1] <= R2_Extern.angle3 + 5 && dm4310_fb[1].position_deg >= R2_Extern.angle2 - 5 && dm4310_fb[1].position_deg <= R2_Extern.angle2 + 5)
                {
                  R2_Extern.KFS_status_flag = 34;
                  // osDelay(500);
                  // R2_Extern.angle2 = 60;
                  // R2_Extern.angle3 = 60;
                  // if(unitree_pos[1]>= R2_Extern.angle3 - 5 && unitree_pos[1] <= R2_Extern.angle3 + 5 && dm4310_fb[1].position_deg >= R2_Extern.angle2 - 5 && dm4310_fb[1].position_deg <= R2_Extern.angle2 + 5)

                  // {
                  //   R2_Extern.KFS_status_flag = 4;
                  // }

                }
            }
        break;

        case 34:
                  R2_Extern.angle2 = 60;
                  R2_Extern.angle3 = 100;
                  if(unitree_pos[1]>= R2_Extern.angle3 - 5 && unitree_pos[1] <= R2_Extern.angle3 + 5 && dm4310_fb[1].position_deg >= R2_Extern.angle2 - 5 && dm4310_fb[1].position_deg <= R2_Extern.angle2 + 5)

                  {
                    R2_Extern.KFS_status_flag = 4;
                  }
        break;
        case 4:
        R2_Extern.angle2 = 0;
        R2_Extern.angle3 = 120;
        if(unitree_pos[1]>= R2_Extern.angle3 - 10 && unitree_pos[1] <= R2_Extern.angle3 + 10 && dm4310_fb[1].position_deg >= R2_Extern.angle2 - 10 && dm4310_fb[1].position_deg <= R2_Extern.angle2 + 10)
        {
          R2_Extern.angle4 = 0;
          if(unitree_pos[1]>= R2_Extern.angle3 - 5 && unitree_pos[1] <= R2_Extern.angle3 + 5 && dm4310_fb[1].position_deg >= R2_Extern.angle2 - 5 && dm4310_fb[1].position_deg <= R2_Extern.angle2 + 50)
          {
            // osDelay(1000);
            if(R2_Extern.KFS_Get_flag == 1)
            {
              osDelay(1000);
              if(R2_Extern.KFS_Get_flag == 1)
              {
                R2_Extern.KFS_status_flag = 0;
                // R2_Extern.KFS_status_flag = 1;
              }
            }
            else
            {
              R2_Extern.KFS_status_flag = 5;
              // R2_Extern.angle4 = -90;
              // R2_Extern.special_flag = 1;
              // R2_Extern.lift_mood = 0;
              // R2_Extern.angle2 = 0;
              // R2_Extern.angle3 = -10;
              // R2_Extern.angle4 = -90;
              // R2_Extern.bool_KFS_flag = 0;
              // R2_Extern.car_flag = 0;
              // R2_Extern.kfs_count ++;
              // R2_Extern.KFS_status_flag = 0;

            }
          }
        }

        case 5:
                R2_Extern.special_flag = 1;
                R2_Extern.lift_mood = 0;
                R2_Extern.angle2 = 0;
                R2_Extern.angle3 = 0;
                R2_Extern.angle4 = -135;
                R2_Extern.bool_KFS_flag = 0;
                R2_Extern.car_flag = 0;
                R2_Extern.kfs_count ++;
                R2_Extern.KFS_status_flag = 0;

        break;

        break;

        case 10:
        R2_Extern.angle1 = 0;
        R2_Extern.angle2 = 50;
        R2_Extern.angle3 = 110;
        R2_Extern.angle4 = -50;
        if(unitree_pos[1]>= R2_Extern.angle3 - 5 && unitree_pos[1] <= R2_Extern.angle3 + 5 && dm4310_fb[1].position_deg >= R2_Extern.angle2 - 5 && dm4310_fb[1].position_deg <= R2_Extern.angle2 + 5)
        {
          fangkuang_close_2();
          osDelay(500);
          R2_Extern.kfs_count ++;
          R2_Extern.KFS_status_flag = 11;

        }
        break;

        case 11:
          R2_Extern.angle1 = 0;
          R2_Extern.angle2 = 10;
          R2_Extern.angle3 = 0;
          R2_Extern.angle4 = -90;
          fangkuang_open_2();
          if(unitree_pos[1]>= R2_Extern.angle3 - 5 && unitree_pos[1] <= R2_Extern.angle3 + 5 && dm4310_fb[1].position_deg >= R2_Extern.angle2 - 5 && dm4310_fb[1].position_deg <= R2_Extern.angle2 + 5)
          {
            R2_Extern.KFS_status_flag = 0;
          }
        break;

        default:
        break;

      }

  }

    osDelay(5);
  }
  /* USER CODE END Two_Area_Function */
}

void Three_Area_Function(void *argument)
{
  /* USER CODE BEGIN Three_Area_Function */
  /* Infinite loop */
  for(;;)
  {
    if(visual_data.hmi_start != 1)
    {
      R2_Extern.angle = 0;
      R2_Extern.speed = 0;
      osDelay(5);
      continue;
    }

    const float (*area_3_dt35)[2] = (R2_Extern.Track_flag == 0) ? area_3_dt35_red : area_3_dt35_blue;
    if(R2_Extern.work_mode == 3)//暂时
    {
      switch (R2_Extern.Area3_step)
      {
      case 0:
      R2_Extern.angle_balance_target =(R2_Extern.Track_flag == 0) ? 90 : -90;
      // R2_Extern.angle1 = 0;
      // R2_Extern.angle2 = 60;
      // R2_Extern.angle3 = 120;
      // R2_Extern.angle4 = 0;
      // R2_Extern.pitch_angle = 10;
      if(R2_Extern.chack_yaw_flag == 1)
      {
        R2_Extern.Area3_step = 1;
        osDelay(500);
      }

        break;

      case 1:
      if(R2_Extern.Area3_flag == 1)
        {
          R2_Extern.Area3_step = 2;
        }
      break;
      case 2:
        // R2_Extern.Area3_cell = visual_data.target_cell - 3;
        R2_Extern.Area3_cell = 1;
        R2_Extern.angle2 = 60;
        R2_Extern.angle3 = 90;
        if(R2_Extern.kfs_count_total == 2)
        {
          R2_Extern.angle4 = -130;
        }
        else
        {
          R2_Extern.angle4 = -40;
        }
        R2_Extern.Area3_step = 3;
        break;
      case 3:
        fangkuang(area_3_dt35[R2_Extern.Area3_cell][0], area_3_dt35[R2_Extern.Area3_cell][1]);
        if(R2_Extern.Area3_2_flag == 1)
        {
          R2_Extern.Area3_step = 4;
        }
        break;

      case 4:
//放的时候先放下面的，再放上面的
        fangkuang_close_1();
        fangkuang_close_2();

        break;

      default:
        break;
      }

    }
    osDelay(1);
  }
  /* USER CODE END Three_Area_Function */
}

void Mid360_Function(void *argument)
{
  /* USER CODE BEGIN Mid360_Function */

  /* Infinite loop */
  for(;;)
  {
    if(visual_data.hmi_start != 1)
    {
      R2_Extern.angle = 0;
      R2_Extern.speed = 0;
      osDelay(5);
      continue;
    }

    const float (*area_1)[2] = (R2_Extern.Track_flag == 0) ? area_1_red : area_1_blue;
    const float (*area_2)[2] = (R2_Extern.Track_flag == 0) ? area_2_red : area_2_blue;
    const float (*area_3)[2] = (R2_Extern.Track_flag == 0) ? area_3_red : area_3_blue;
    const float (*data_table)[2] = (R2_Extern.Track_flag == 0) ? data_table_red : data_table_blue;

    if(visual_data.i == 1)
    {
      if (visual_data.workl_mode == 1)
      {
        switch(R2_Extern.Area1_step)
        {
          case 0:
          if(R2_Extern.Area1_1_flag == 0)
          {
            chassic_control_auto(&chassic_data, visual_data.x_map, visual_data.y_map, area_1[0][0], area_1[0][1] , 1.0);
            R2_Extern.angle = chassic_data.angle;
            R2_Extern.speed = chassic_data.distance;
            check_dingwei_2(visual_data.x_map, visual_data.y_map, area_1[0][0], area_1[0][1]);
            if(R2_Extern.bool_check_1_flag == 1)
            {
              R2_Extern.angle = 0;
              R2_Extern.speed = 0;
              R2_Extern.Area1_1_flag =1;
              R2_Extern.Area1_step = 1;
            }
          }
          break;

          case 1:
          break;

          default:
          break;
        }

      }

      if(visual_data.workl_mode == 2)
      {
        if(R2_Extern.complete_taijie_flag == 1 && R2_Extern.complete_dingwei_flag == 0 && R2_Extern.start_sanqugoon_flag == 0 && R2_Extern.chack_yaw_flag == 1)
        {
          uint8_t current_cell = visual_data.meilin_points[R2_Extern.meilin_count_flag].cell;
          if(current_cell >= 1 && current_cell <= 12)
          {
            chassic_control_auto(&chassic_data, visual_data.x_map, visual_data.y_map, data_table[current_cell-1][0], data_table[current_cell-1][1] , 2.0);
            R2_Extern.angle = chassic_data.angle;
            R2_Extern.speed = chassic_data.distance;
          }
          else
          {
              R2_Extern.angle = 0;
              R2_Extern.speed = 0;
          }
        }
        else if(R2_Extern.start_sanqugoon_flag == 1)
        {
          // 三圈果定位：依次经过两个中间点
          float dx1 = visual_data.x_map - area_2[0][0];
          float dy1 = visual_data.y_map - area_2[0][1];
          float dist1 = sqrtf(dx1 * dx1 + dy1 * dy1);

          float dx2 = visual_data.x_map - area_2[1][0];
          float dy2 = visual_data.y_map - area_2[1][1];
          float dist2 = sqrtf(dx2 * dx2 + dy2 * dy2);

          switch(R2_Extern.sanqugoon_step)
          {
            case 0:
              if(dist1 <= 0.10f)
              {
                R2_Extern.sanqugoon_step = 1; // 切换到点2
              }
              else
              {
                chassic_control_auto(&chassic_data, visual_data.x_map, visual_data.y_map, area_2[0][0], area_2[0][1] , 1.0);
                R2_Extern.angle = chassic_data.angle;
                R2_Extern.speed = chassic_data.distance;
              }
              break;

            case 1: // 走向点2 (11.02, -4.24)
              if(dist2 <= 0.10f)
              {
                R2_Extern.complete_dingwei_flag = 1;
                R2_Extern.angle = 0;
                R2_Extern.speed = 0;
                R2_Extern.work_mode = 3;
              }
              else
              {
                chassic_control_auto(&chassic_data, visual_data.x_map, visual_data.y_map, area_2[1][0], area_2[1][1] , 1.5);
                R2_Extern.angle = chassic_data.angle;
                R2_Extern.speed = chassic_data.distance;
              }
              break;

            default:
              break;
          }
        }
      }

      if(visual_data.workl_mode == 3)
      {
        if(R2_Extern.Area3_flag == 0 && R2_Extern.Area3_step == 1)
        {
          chassic_control_auto(&chassic_data, visual_data.x_map, visual_data.y_map, area_3[0][0], area_3[0][1] , 1.0);
          R2_Extern.angle = chassic_data.angle;
          R2_Extern.speed = chassic_data.distance;
          check_dingwei_2(visual_data.x_map, visual_data.y_map, area_3[0][0], area_3[0][1]);
          {
            if(R2_Extern.bool_check_1_flag == 1)
            {
              R2_Extern.Area3_flag =1;
            }
          }
        }
      }

    }

    osDelay(5);
  }
  /* USER CODE END Mid360_Function */
}

void Track_Mode_Function(void *argument)
{
  /* USER CODE BEGIN Track_Mode_Function */
  /* Infinite loop */
  for(;;)
  {
    if(visual_data.hmi_color == 1)
    {
      R2_Extern.Track_flag = 0;//红
      RGB_Color_Ctrl(1,255,1);//绿
    }
    else if (visual_data.hmi_color == 2)
    {
      R2_Extern.Track_flag = 1;//蓝
      RGB_Color_Ctrl(255,255,1);//黄
    }
    osDelay(10);
  }
  /* USER CODE END Track_Mode_Function */
}
